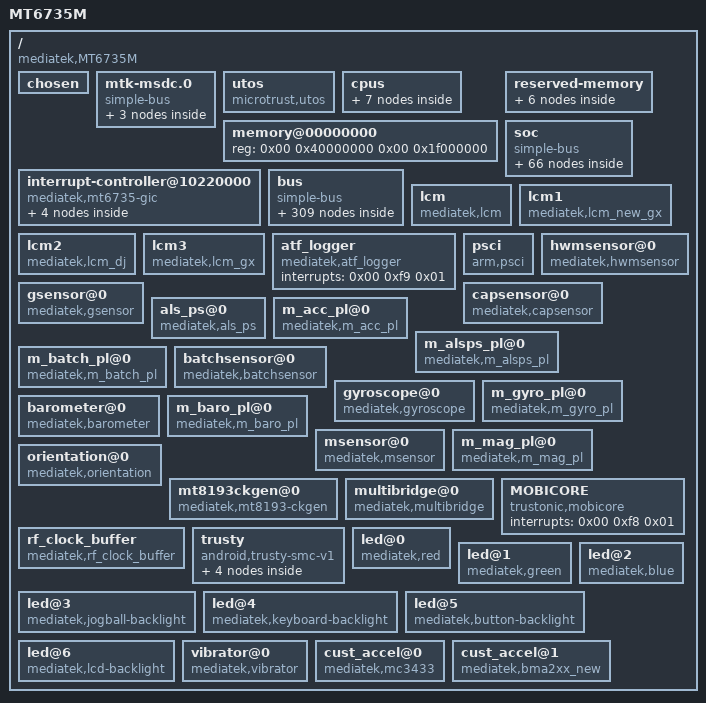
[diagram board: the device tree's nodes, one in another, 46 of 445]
/dts-v1/;

/ {
	model = "MT6735M";
	compatible = "mediatek,MT6735M";
	interrupt-parent = <0x01>;
	#address-cells = <0x02>;
	#size-cells = <0x02>;

	chosen {
		bootargs = "console=tty0 console=ttyMT0,921600n1 root=/dev/ram initrd=0x44000000,0x1000000 loglevel=8 androidboot.hardware=mt6735";
	};

	mtk-msdc.0 {
		compatible = "simple-bus";
		#address-cells = <0x01>;
		#size-cells = <0x01>;
		ranges = <0x00 0x00 0x00 0xffffffff>;

		msdc0@11230000 {
			compatible = "mediatek,mt6735m-mmc";
			reg = <0x11230000 0x10000 0x10000e84 0x02>;
			interrupts = <0x00 0x4f 0x08>;
			status = "okay";
			clk_src = [02];
			bus-width = <0x08>;
			max-frequency = <0xbebc200>;
			cap-mmc-highspeed;
			msdc-sys-suspend;
			mmc-ddr-1_8v;
			mmc-hs200-1_8v;
			mmc-hs400-1_8v;
			non-removable;
			pinctl = <0x02>;
			register_setting = <0x03>;
			host_function = [00];
			bootable;
		};

		msdc1@11240000 {
			compatible = "mediatek,mt6735m-mmc";
			reg = <0x11240000 0x10000 0x10000e84 0x02>;
			interrupts = <0x00 0x50 0x08>;
			status = "okay";
			clk_src = [02];
			bus-width = <0x04>;
			max-frequency = <0xbebc200>;
			msdc-sys-suspend;
			sd_need_power;
			cap-sd-highspeed;
			sd-uhs-sdr12;
			sd-uhs-sdr25;
			sd-uhs-sdr50;
			sd-uhs-sdr104;
			sd-uhs-ddr50;
			pinctl = <0x04>;
			pinctl_sdr104 = <0x05>;
			pinctl_sdr50 = <0x06>;
			pinctl_ddr50 = <0x07>;
			register_setting = <0x08>;
			host_function = [01];
			cd_level = [01];
			cd-gpios = <0x09 0x0b 0x00>;
		};

		default {
			compatible = "mediatek, msdc1_ins-eint";
			interrupt-parent = <0x0a>;
			interrupts = <0x0b 0x08>;
			debounce = <0x0b 0x3e8>;
			status = "okay";
		};
	};

	utos {
		compatible = "microtrust,utos";
		interrupts = <0x00 0xf4 0x01 0x00 0xf5 0x01 0x00 0xf6 0x01 0x00 0xfa 0x01 0x00 0xfb 0x01 0x00 0xfc 0x01 0x00 0xfd 0x01 0x00 0xff 0x01>;
	};

	cpus {
		#address-cells = <0x01>;
		#size-cells = <0x00>;

		cpu@000 {
			device_type = "cpu";
			compatible = "arm,cortex-a53";
			reg = <0x00>;
			enable-method = "mt-boot";
			cpu-idle-states = <0x0b 0x0b 0x0c 0x0c>;
			cpu-release-addr = <0x00 0x40000200>;
			clock-frequency = <0x3b9aca00>;
			linux,phandle = <0x0d>;
			phandle = <0x0d>;
		};

		cpu@001 {
			device_type = "cpu";
			compatible = "arm,cortex-a53";
			reg = <0x01>;
			enable-method = "mt-boot";
			cpu-idle-states = <0x0b 0x0b 0x0c 0x0c>;
			cpu-release-addr = <0x00 0x40000200>;
			clock-frequency = <0x3b9aca00>;
			linux,phandle = <0x0e>;
			phandle = <0x0e>;
		};

		cpu@002 {
			device_type = "cpu";
			compatible = "arm,cortex-a53";
			reg = <0x02>;
			enable-method = "mt-boot";
			cpu-idle-states = <0x0b 0x0b 0x0c 0x0c>;
			cpu-release-addr = <0x00 0x40000200>;
			clock-frequency = <0x3b9aca00>;
			linux,phandle = <0x0f>;
			phandle = <0x0f>;
		};

		cpu@003 {
			device_type = "cpu";
			compatible = "arm,cortex-a53";
			reg = <0x03>;
			enable-method = "mt-boot";
			cpu-idle-states = <0x0b 0x0b 0x0c 0x0c>;
			cpu-release-addr = <0x00 0x40000200>;
			clock-frequency = <0x3b9aca00>;
			linux,phandle = <0x10>;
			phandle = <0x10>;
		};

		idle-states {
			entry-method = "arm,psci";

			cpu-sleep-0-0 {
				compatible = "arm,idle-state";
				arm,psci-suspend-param = <0x10000>;
				entry-latency-us = <0x258>;
				exit-latency-us = <0x258>;
				min-residency-us = <0x4b0>;
				linux,phandle = <0x0c>;
				phandle = <0x0c>;
			};

			cluster-sleep-0 {
				compatible = "arm,idle-state";
				arm,psci-suspend-param = <0x1010000>;
				entry-latency-us = <0x320>;
				exit-latency-us = <0x3e8>;
				min-residency-us = <0x7d0>;
				linux,phandle = <0x0b>;
				phandle = <0x0b>;
			};
		};
	};

	memory@00000000 {
		device_type = "memory";
		reg = <0x00 0x40000000 0x00 0x1f000000>;
	};

	reserved-memory {
		#address-cells = <0x02>;
		#size-cells = <0x02>;
		ranges;

		atf-reserved-memory@43000000 {
			compatible = "mediatek,mt6735-atf-reserved-memory", "mediatek,mt6735m-atf-reserved-memory", "mediatek,mt6753-atf-reserved-memory";
			no-map;
			reg = <0x00 0x43000000 0x00 0x30000>;
		};

		reserve-memory-ccci_md1 {
			compatible = "mediatek,reserve-memory-ccci_md1";
			no-map;
			size = <0x00 0x3810000>;
			alignment = <0x00 0x2000000>;
			alloc-ranges = <0x00 0x40000000 0x00 0xc0000000>;
		};

		consys-reserve-memory {
			compatible = "mediatek,consys-reserve-memory";
			no-map;
			size = <0x00 0x100000>;
			alignment = <0x00 0x200000>;
		};

		ram_console-reserved-memory@43f00000 {
			compatible = "mediatek,ram_console";
			reg = <0x00 0x43f00000 0x00 0x10000>;
		};

		minirdump-reserved-memory@43ff0000 {
			compatible = "mediatek, minirdump";
			reg = <0x00 0x43ff0000 0x00 0x10000>;
		};

		pstore-reserved-memory@43f10000 {
			compatible = "mediatek,pstore";
			reg = <0x00 0x43f10000 0x00 0xe0000>;
		};
	};

	interrupt-controller@10220000 {
		compatible = "mediatek,mt6735-gic";
		#interrupt-cells = <0x03>;
		#address-cells = <0x00>;
		interrupt-controller;
		reg = <0x00 0x10221000 0x00 0x1000 0x00 0x10222000 0x00 0x1000 0x00 0x10200620 0x00 0x1000>;
		mediatek,wdt_irq = <0xa0>;
		linux,phandle = <0x01>;
		phandle = <0x01>;

		gic-cpuif@0 {
			compatible = "arm,gic-cpuif";
			cpuif-id = <0x00>;
			cpu = <0x0d>;
		};

		gic-cpuif@1 {
			compatible = "arm,gic-cpuif";
			cpuif-id = <0x01>;
			cpu = <0x0e>;
		};

		gic-cpuif@2 {
			compatible = "arm,gic-cpuif";
			cpuif-id = <0x02>;
			cpu = <0x0f>;
		};

		gic-cpuif@3 {
			compatible = "arm,gic-cpuif";
			cpuif-id = <0x03>;
			cpu = <0x10>;
		};
	};

	soc {
		compatible = "simple-bus";
		#address-cells = <0x01>;
		#size-cells = <0x01>;
		ranges;

		gpio {
			compatible = "mediatek,gpio_usage_mapping";
			GPIO_SIM1_SCLK = <0xa3>;
			GPIO_SIM1_SRST = <0xa4>;
			GPIO_SIM1_SIO = <0xa5>;
		};

		gpio@10211000 {
			compatible = "mediatek,gpio";
			reg = <0x10211000 0x1000>;
		};

		dramc_nao@1020e000 {
			compatible = "mediatek,mt6735-dramc_nao";
			reg = <0x1020e000 0x1000>;
		};

		ddrphy@10213000 {
			compatible = "mediatek,mt6735-ddrphy";
			reg = <0x10213000 0x1000>;
		};

		dramc@10214000 {
			compatible = "mediatek,mt6735-dramc";
			reg = <0x10214000 0x1000>;
			clock-names = "infra-cqdma";
		};

		cpuxgpt@10200000 {
			compatible = "mediatek,mt6735-cpuxgpt";
			reg = <0x10200000 0x1000>;
			interrupts = <0x00 0x40 0x04 0x00 0x41 0x04 0x00 0x42 0x04 0x00 0x43 0x04 0x00 0x44 0x04 0x00 0x45 0x04 0x00 0x46 0x04 0x00 0x47 0x04>;
		};

		apxgpt@10004000 {
			compatible = "mediatek,mt6735-apxgpt";
			reg = <0x10004000 0x1000>;
			interrupts = <0x00 0x98 0x08>;
			clock-frequency = <0xc65d40>;
		};

		pmu {
			compatible = "arm,armv8-pmuv3";
			interrupts = <0x00 0x08 0x08 0x00 0x09 0x08 0x00 0x0a 0x08 0x00 0x0b 0x08>;
			interrupt-affinity = <0x0d 0x0e 0x0f 0x10>;
		};

		timer {
			compatible = "arm,armv8-timer";
			interrupts = <0x01 0x0d 0x08 0x01 0x0e 0x08 0x01 0x0b 0x08 0x01 0x0a 0x08>;
			clock-frequency = <0xc65d40>;
		};

		mt_pmic_regulator {
			compatible = "mediatek,mt_pmic";

			buck_regulators {
				compatible = "mediatek,mt_pmic_buck_regulators";

				buck_vpa {
					regulator-name = "vpa";
					regulator-min-microvolt = <0x7a120>;
					regulator-max-microvolt = <0x37b1d0>;
					regulator-ramp-delay = <0xc350>;
					regulator-enable-ramp-delay = <0xb4>;
				};

				buck_vproc {
					regulator-name = "vproc";
					regulator-min-microvolt = <0x927c0>;
					regulator-max-microvolt = <0x154456>;
					regulator-ramp-delay = <0x186a>;
					regulator-enable-ramp-delay = <0xb4>;
					regulator-always-on;
					regulator-boot-on;
				};

				buck_vcore1 {
					regulator-name = "vcore1";
					regulator-min-microvolt = <0x927c0>;
					regulator-max-microvolt = <0x154456>;
					regulator-ramp-delay = <0x186a>;
					regulator-enable-ramp-delay = <0xb4>;
					regulator-always-on;
					regulator-boot-on;
				};

				buck_vsys22 {
					regulator-name = "vsys22";
					regulator-min-microvolt = <0x124f80>;
					regulator-max-microvolt = <0x1e6c16>;
					regulator-ramp-delay = <0x186a>;
					regulator-enable-ramp-delay = <0xb4>;
					regulator-always-on;
					regulator-boot-on;
				};

				buck_vlte {
					regulator-name = "vlte";
					regulator-min-microvolt = <0x927c0>;
					regulator-max-microvolt = <0x154456>;
					regulator-ramp-delay = <0x186a>;
					regulator-enable-ramp-delay = <0xb4>;
					regulator-always-on;
					regulator-boot-on;
				};
			};

			ldo_regulators {
				compatible = "mediatek,mt_pmic_ldo_regulators";

				ldo_vaux18 {
					regulator-name = "vaux18";
					regulator-min-microvolt = <0x1b7740>;
					regulator-max-microvolt = <0x1b7740>;
					regulator-enable-ramp-delay = <0x108>;
					regulator-boot-on;
					linux,phandle = <0x11>;
					phandle = <0x11>;
				};

				ldo_vtcxo_0 {
					regulator-name = "vtcxo_0";
					regulator-min-microvolt = <0x2ab980>;
					regulator-max-microvolt = <0x2ab980>;
					regulator-enable-ramp-delay = <0x6e>;
					regulator-boot-on;
					linux,phandle = <0x12>;
					phandle = <0x12>;
				};

				ldo_vtcxo_1 {
					regulator-name = "vtcxo_1";
					regulator-min-microvolt = <0x2ab980>;
					regulator-max-microvolt = <0x2ab980>;
					regulator-enable-ramp-delay = <0x6e>;
					linux,phandle = <0x13>;
					phandle = <0x13>;
				};

				ldo_vaud28 {
					regulator-name = "vaud28";
					regulator-min-microvolt = <0x2ab980>;
					regulator-max-microvolt = <0x2ab980>;
					regulator-enable-ramp-delay = <0x108>;
					regulator-boot-on;
					linux,phandle = <0x14>;
					phandle = <0x14>;
				};

				ldo_vcn28 {
					regulator-name = "vcn28";
					regulator-min-microvolt = <0x2ab980>;
					regulator-max-microvolt = <0x2ab980>;
					regulator-enable-ramp-delay = <0x108>;
					linux,phandle = <0x24>;
					phandle = <0x24>;
				};

				ldo_vcama {
					regulator-name = "vcama";
					regulator-min-microvolt = <0x16e360>;
					regulator-max-microvolt = <0x2ab980>;
					regulator-enable-ramp-delay = <0x108>;
					regulator-default-on = <0x00>;
					status = "okay";
					linux,phandle = <0x4f>;
					phandle = <0x4f>;
				};

				ldo_vcn33_bt {
					regulator-name = "vcn33_bt";
					regulator-min-microvolt = <0x325aa0>;
					regulator-max-microvolt = <0x36ee80>;
					regulator-enable-ramp-delay = <0x108>;
					linux,phandle = <0x25>;
					phandle = <0x25>;
				};

				ldo_vcn33_wifi {
					regulator-name = "vcn33_wifi";
					regulator-min-microvolt = <0x325aa0>;
					regulator-max-microvolt = <0x36ee80>;
					regulator-enable-ramp-delay = <0x108>;
					linux,phandle = <0x26>;
					phandle = <0x26>;
				};

				ldo_vusb33 {
					regulator-name = "vusb33";
					regulator-min-microvolt = <0x325aa0>;
					regulator-max-microvolt = <0x325aa0>;
					regulator-enable-ramp-delay = <0x108>;
					regulator-boot-on;
				};

				ldo_vefuse {
					regulator-name = "vefuse";
					regulator-min-microvolt = <0x1b7740>;
					regulator-max-microvolt = <0x2191c0>;
					regulator-enable-ramp-delay = <0x108>;
					linux,phandle = <0x15>;
					phandle = <0x15>;
				};

				ldo_vsim1 {
					regulator-name = "vsim1";
					regulator-min-microvolt = <0x19f0a0>;
					regulator-max-microvolt = <0x200b20>;
					regulator-enable-ramp-delay = <0x108>;
					regulator-default-on = <0x00>;
					status = "okay";
					linux,phandle = <0x16>;
					phandle = <0x16>;
				};

				ldo_vsim2 {
					regulator-name = "vsim2";
					regulator-min-microvolt = <0x19f0a0>;
					regulator-max-microvolt = <0x200b20>;
					regulator-enable-ramp-delay = <0x108>;
					regulator-default-on = <0x00>;
					status = "okay";
					linux,phandle = <0x17>;
					phandle = <0x17>;
				};

				ldo_vemc_3v3 {
					regulator-name = "vemc_3v3";
					regulator-min-microvolt = <0x1b7740>;
					regulator-max-microvolt = <0x325aa0>;
					regulator-enable-ramp-delay = <0x108>;
					regulator-boot-on;
					linux,phandle = <0x18>;
					phandle = <0x18>;
				};

				ldo_vmch {
					regulator-name = "vmch";
					regulator-min-microvolt = <0x2c4020>;
					regulator-max-microvolt = <0x325aa0>;
					regulator-enable-ramp-delay = <0x2c>;
					linux,phandle = <0x19>;
					phandle = <0x19>;
				};

				ldo_vtref {
					regulator-name = "vtref";
					regulator-min-microvolt = <0x1b7740>;
					regulator-max-microvolt = <0x1b7740>;
					regulator-enable-ramp-delay = <0xf0>;
					linux,phandle = <0x1a>;
					phandle = <0x1a>;
				};

				ldo_vmc {
					regulator-name = "vmc";
					regulator-min-microvolt = <0x1b7740>;
					regulator-max-microvolt = <0x325aa0>;
					regulator-enable-ramp-delay = <0x2c>;
					linux,phandle = <0x1b>;
					phandle = <0x1b>;
				};

				ldo_vcamaf {
					regulator-name = "vcamaf";
					regulator-min-microvolt = <0x124f80>;
					regulator-max-microvolt = <0x325aa0>;
					regulator-enable-ramp-delay = <0x108>;
					regulator-default-on = <0x00>;
					status = "okay";
					linux,phandle = <0x51>;
					phandle = <0x51>;
				};

				ldo_vio28 {
					regulator-name = "vio28";
					regulator-min-microvolt = <0x2ab980>;
					regulator-max-microvolt = <0x2ab980>;
					regulator-enable-ramp-delay = <0x108>;
					regulator-boot-on;
					linux,phandle = <0x1c>;
					phandle = <0x1c>;
				};

				ldo_vgp1 {
					regulator-name = "vgp1";
					regulator-min-microvolt = <0x124f80>;
					regulator-max-microvolt = <0x325aa0>;
					regulator-enable-ramp-delay = <0x108>;
					regulator-default-on = <0x00>;
					status = "okay";
					linux,phandle = <0x36>;
					phandle = <0x36>;
				};

				ldo_vibr {
					regulator-name = "vibr";
					regulator-min-microvolt = <0x124f80>;
					regulator-max-microvolt = <0x325aa0>;
					regulator-enable-ramp-delay = <0x2c>;
					regulator-default-on = <0x00>;
					status = "okay";
					linux,phandle = <0x1d>;
					phandle = <0x1d>;
				};

				ldo_vcamd {
					regulator-name = "vcamd";
					regulator-min-microvolt = <0xdbba0>;
					regulator-max-microvolt = <0x16e360>;
					regulator-enable-ramp-delay = <0x108>;
					regulator-default-on = <0x00>;
					status = "okay";
					linux,phandle = <0x50>;
					phandle = <0x50>;
				};

				ldo_vrf18_0 {
					regulator-name = "vrf18_0";
					regulator-min-microvolt = <0x1bd8e8>;
					regulator-max-microvolt = <0x1bd8e8>;
					regulator-enable-ramp-delay = <0xdc>;
					linux,phandle = <0x1e>;
					phandle = <0x1e>;
				};

				ldo_vrf18_1 {
					regulator-name = "vrf18_1";
					regulator-min-microvolt = <0x124f80>;
					regulator-max-microvolt = <0x1bd8e8>;
					regulator-enable-ramp-delay = <0xdc>;
					linux,phandle = <0x1f>;
					phandle = <0x1f>;
				};

				ldo_vio18 {
					regulator-name = "vio18";
					regulator-min-microvolt = <0x1b7740>;
					regulator-max-microvolt = <0x1b7740>;
					regulator-enable-ramp-delay = <0x108>;
					regulator-boot-on;
					linux,phandle = <0x20>;
					phandle = <0x20>;
				};

				ldo_vcn18 {
					regulator-name = "vcn18";
					regulator-min-microvolt = <0x1b7740>;
					regulator-max-microvolt = <0x1b7740>;
					regulator-enable-ramp-delay = <0x2c>;
					linux,phandle = <0x23>;
					phandle = <0x23>;
				};

				ldo_vcamio {
					regulator-name = "vcamio";
					regulator-min-microvolt = <0x124f80>;
					regulator-max-microvolt = <0x1b7740>;
					regulator-enable-ramp-delay = <0xdc>;
					regulator-default-on = <0x00>;
					status = "okay";
					linux,phandle = <0x52>;
					phandle = <0x52>;
				};

				ldo_vsram {
					regulator-name = "vsram";
					regulator-min-microvolt = <0xaae60>;
					regulator-max-microvolt = <0x16caf6>;
					regulator-enable-ramp-delay = <0xdc>;
					regulator-ramp-delay = <0x186a>;
					regulator-boot-on;
					linux,phandle = <0x21>;
					phandle = <0x21>;
				};

				ldo_vm {
					regulator-name = "vm";
					regulator-min-microvolt = <0x12ebc0>;
					regulator-max-microvolt = <0x177fa0>;
					regulator-enable-ramp-delay = <0x108>;
					regulator-boot-on;
					linux,phandle = <0x22>;
					phandle = <0x22>;
				};
			};

			regulators_supply {
				compatible = "mediatek,mt_pmic_regulator_supply";
				vaux18-supply = <0x11>;
				vtcxo_0-supply = <0x12>;
				vtcxo_1-supply = <0x13>;
				vaud28-supply = <0x14>;
				vefuse-supply = <0x15>;
				vsim1-supply = <0x16>;
				vsim2-supply = <0x17>;
				vemc_3v3-supply = <0x18>;
				vmch-supply = <0x19>;
				vtref-supply = <0x1a>;
				vmc-supply = <0x1b>;
				vio28-supply = <0x1c>;
				vibr-supply = <0x1d>;
				vrf18_0-supply = <0x1e>;
				vrf18_1-supply = <0x1f>;
				vio18-supply = <0x20>;
				vsram-supply = <0x21>;
				vm-supply = <0x22>;
			};
		};

		toprgu@10212000 {
			compatible = "mediatek,mt6735-rgu";
			reg = <0x10212000 0x1000>;
			interrupts = <0x00 0x80 0x02>;
		};

		mcu_biu@10300000 {
			compatible = "mediatek,mt6735-mcu_biu";
			reg = <0x10300000 0x8000>;
		};

		keypad@10003000 {
			compatible = "mediatek,mt6735-keypad", "mediatek,mt6735m-keypad";
			reg = <0x10003000 0x1000>;
			interrupts = <0x00 0xa4 0x02>;
			mediatek,kpd-key-debounce = <0x400>;
			mediatek,kpd-sw-pwrkey = <0x74>;
			mediatek,kpd-hw-pwrkey = <0x08>;
			mediatek,kpd-use-extend-type = <0x00>;
			mediatek,kpd-hw-map-num = <0x48>;
			mediatek,kpd-hw-init-map = <0x73 0x72 0x00 0x00 0x00 0x00 0x00 0x00 0x00 0x00 0x00 0x00 0x00 0x00 0x00 0x00 0x00 0x00 0x00 0x00 0x00 0x00 0x00 0x00 0x00 0x00 0x00 0x00 0x00 0x00 0x00 0x00 0x00 0x00 0x00 0x00 0x00 0x00 0x00 0x00 0x00 0x00 0x00 0x00 0x00 0x00 0x00 0x00 0x00 0x00 0x00 0x00 0x00 0x00 0x00 0x00 0x00 0x00 0x00 0x00 0x00 0x00 0x00 0x00 0x00 0x00 0x00 0x00 0x00 0x00 0x00 0x00>;
			mediatek,kpd-pwrkey-eint-gpio = <0x00>;
			mediatek,kpd-pwkey-gpio-din = <0x00>;
			mediatek,kpd-hw-dl-key0 = <0x00>;
			mediatek,kpd-hw-dl-key1 = <0x01>;
			mediatek,kpd-hw-dl-key2 = <0x08>;
			mediatek,kpd-hw-recovery-key = <0x00>;
			mediatek,kpd-hw-factory-key = <0x01>;
			status = "okay";
		};

		irtx@11011000 {
			compatible = "mediatek,irtx";
			reg = <0x11011000 0x1000>;
			interrupts = <0x00 0x7c 0x04>;
			pwm_ch = <0x00>;
		};

		apuart0@11002000 {
			cell-index = <0x00>;
			compatible = "mediatek,mt6735-uart";
			reg = <0x11002000 0x1000 0x11000380 0x1000 0x11000400 0x80>;
			interrupts = <0x00 0x5b 0x08 0x00 0x67 0x08 0x00 0x68 0x08>;
		};

		apuart1@11003000 {
			cell-index = <0x01>;
			compatible = "mediatek,mt6735-uart";
			reg = <0x11003000 0x1000 0x11000480 0x80 0x11000500 0x80>;
			interrupts = <0x00 0x5c 0x08 0x00 0x69 0x08 0x00 0x6a 0x08>;
		};

		apuart2@11004000 {
			cell-index = <0x02>;
			compatible = "mediatek,mt6735-uart";
			reg = <0x11004000 0x1000 0x11000580 0x80 0x11000600 0x80>;
			interrupts = <0x00 0x5d 0x08 0x00 0x6b 0x08 0x00 0x6c 0x08>;
		};

		apuart3@11005000 {
			cell-index = <0x03>;
			compatible = "mediatek,mt6735-uart";
			reg = <0x11005000 0x1000 0x11000680 0x80 0x11000700 0x80>;
			interrupts = <0x00 0x5e 0x08 0x00 0x6d 0x08 0x00 0x6e 0x08>;
		};

		spi@1100a000 {
			compatible = "mediatek,mt6735m-spi";
			cell-index = <0x00>;
			spi-padmacro = <0x00>;
			reg = <0x1100a000 0x1000>;
			interrupts = <0x00 0x76 0x08>;
		};

		btif_tx@11000780 {
			compatible = "mediatek,btif_tx";
			reg = <0x11000780 0x80>;
			interrupts = <0x00 0x6f 0x08>;
		};

		btif_rx@11000800 {
			compatible = "mediatek,btif_rx";
			reg = <0x11000800 0x80>;
			interrupts = <0x00 0x70 0x08>;
		};

		btif@1100c000 {
			compatible = "mediatek,btif";
			reg = <0x1100c000 0x1000>;
			interrupts = <0x00 0x5a 0x08>;
		};

		consys@18070000 {
			compatible = "mediatek,mt6735m-consys", "mediatek,mt6735-consys";
			reg = <0x18070000 0x200 0x10212000 0x100 0x10000000 0x2000 0x10006000 0x1000>;
			interrupts = <0x00 0xe3 0x08 0x00 0xe1 0x08>;
			vcn18-supply = <0x23>;
			vcn28-supply = <0x24>;
			vcn33_bt-supply = <0x25>;
			vcn33_wifi-supply = <0x26>;
			pinctrl-names = "default", "gps_lna_state_init", "gps_lna_state_oh", "gps_lna_state_ol";
			pinctrl-0 = <0x27>;
			pinctrl-1 = <0x28>;
			pinctrl-2 = <0x29>;
			pinctrl-3 = <0x2a>;
			status = "okay";
		};

		hacc@10008000 {
			compatible = "mediatek,hacc";
			reg = <0x10008000 0x1000>;
			interrupts = <0x00 0xae 0x08>;
		};

		als {
			compatible = "mediatek, als-eint";
		};

		cap_sensor {
			compatible = "mediatek, cap_sensor-eint";
			interrupt-parent = <0x0a>;
			interrupts = <0x04 0x02>;
			debounce = <0x04 0x00>;
			status = "okay";
		};

		gse_1 {
			compatible = "mediatek, gse_1-eint";
			status = "okay";
			interrupt-parent = <0x0a>;
			interrupts = <0x42 0x08>;
			debounce = <0x42 0x00>;
		};

		ext_buck_oc {
			compatible = "mediatek, ext_buck_oc-eint";
			status = "disabled";
		};

		swtp {
			compatible = "mediatek, swtp-eint";
		};

		dsi_te {
			compatible = "mediatek, dsi_te_1-eint";
			status = "disabled";
		};
	};

	bus {
		compatible = "simple-bus";
		#address-cells = <0x01>;
		#size-cells = <0x01>;
		ranges = <0x00 0x00 0x00 0xffffffff>;

		INFRACFG_AO@0x10000000 {
			compatible = "mediatek,INFRACFG_AO";
			reg = <0x10000000 0x1000>;
		};

		usb2jtag@10000000 {
			compatible = "mediatek,usb2jtag_v1";
			reg = <0x10000000 0x1000 0x11210000 0x1000>;
		};

		PWRAP@0x10001000 {
			compatible = "mediatek,PWRAP";
			reg = <0x10001000 0x1000>;
			interrupts = <0x00 0xa3 0x04>;
		};

		PERICFG@0x10002000 {
			compatible = "mediatek,PERICFG";
			reg = <0x10002000 0x1000>;
		};

		FHCTL@0x10209F00 {
			compatible = "mediatek,FHCTL";
			reg = <0x10209f00 0x100>;
		};

		KP@0x10003000 {
			compatible = "mediatek,KP";
			reg = <0x10003000 0x1000>;
			interrupts = <0x00 0xa4 0x02>;
		};

		eintc@10005000 {
			compatible = "mediatek,mt-eic";
			reg = <0x10005000 0x1000>;
			interrupts = <0x00 0x99 0x04>;
			#interrupt-cells = <0x02>;
			interrupt-controller;
			mediatek,max_eint_num = <0xd5>;
			mediatek,mapping_table_entry = <0x00>;
			mediatek,debtime_setting_entry = <0x0a>;
			mediatek,debtime_setting_array = <0x00 0x7d 0x01 0xfa 0x02 0x1f4 0x03 0x3e8 0x04 0x3e80 0x05 0x7d00 0x06 0xfa00 0x07 0x1f400 0x08 0x3e800 0x09 0x7d000>;
			linux,phandle = <0x0a>;
			phandle = <0x0a>;

			MD1_SIM1_HOT_PLUG_EINT@0 {
				compatible = "mediatek,MD1_SIM1_HOT_PLUG_EINT-eint";
				interrupts = <0x00 0x08>;
				debounce = <0x00 0x186a0>;
				dedicated = <0x00 0x00>;
				src_pin = <0x00 0x01>;
				sockettype = <0x00 0x00>;
				status = "okay";
			};

			pmic@206 {
				compatible = "mediatek, pmic-eint";
				interrupt-parent = <0x0a>;
				interrupts = <0xce 0x04>;
				debounce = <0xce 0x3e8>;
			};
		};

		SLEEP@0x10006000 {
			compatible = "mediatek,SLEEP";
			reg = <0x10006000 0x1000>;
			interrupts = <0x00 0xa5 0x08 0x00 0xa6 0x08 0x00 0xa7 0x08 0x00 0xa8 0x08>;
		};

		DEVAPC_AO@10007000 {
			compatible = "mediatek,DEVAPC_AO";
			reg = <0x10007000 0x1000>;
		};

		RSVD@0x10009000 {
			compatible = "mediatek,RSVD";
			reg = <0x10009000 0x1000>;
		};

		bat_meter {
			compatible = "mediatek,bat_meter";
			r_bat_sense = <0x04>;
			r_i_sense = <0x04>;
			r_charger_1 = <0x14a>;
			r_charger_2 = <0x27>;
			temperature_t0 = <0x6e>;
			temperature_t1 = <0x00>;
			temperature_t2 = <0x19>;
			temperature_t3 = <0x32>;
			temperature_t = <0xff>;
			fg_meter_resistance = <0x00>;
			q_max_pos_50 = <0xda7>;
			q_max_pos_25 = <0xdbb>;
			q_max_pos_0 = <0xdc3>;
			q_max_neg_10 = <0xd40>;
			q_max_pos_50_h_current = <0xd8f>;
			q_max_pos_25_h_current = <0xda2>;
			q_max_pos_0_h_current = <0xd1b>;
			q_max_neg_10_h_current = <0x83a>;
			oam_d5 = <0x00>;
			change_tracking_point = <0x01>;
			cust_tracking_point = <0x0e>;
			cust_r_sense = <0xc8>;
			cust_hw_cc = <0x00>;
			aging_tuning_value = <0x64>;
			cust_r_fg_offset = <0x00>;
			ocv_board_compesate = <0x00>;
			r_fg_board_base = <0x3e8>;
			r_fg_board_slope = <0x3e8>;
			car_tune_value = <0x63>;
			current_detect_r_fg = <0x0a>;
			minerroroffset = <0x3e8>;
			fg_vbat_average_size = <0x12>;
			r_fg_value = <0x0a>;
			cust_poweron_delta_capacity_tolrance = <0x50>;
			cust_poweron_low_capacity_tolrance = <0x02>;
			cust_poweron_max_vbat_tolrance = <0x46>;
			cust_poweron_delta_vbat_tolrance = <0x3c>;
			cust_poweron_delta_hw_sw_ocv_capacity_tolrance = <0x0a>;
			fixed_tbat_25 = <0x00>;
			vbat_normal_wakeup = <0xe10>;
			vbat_low_power_wakeup = <0xdac>;
			normal_wakeup_period = <0x1518>;
			low_power_wakeup_period = <0x12c>;
			close_poweroff_wakeup_period = <0x1e>;
			rbat_pull_up_r = <0x4204>;
			rbat_pull_up_volt = <0x708>;
			batt_temperature_table_num = <0x11>;
			batt_temperature_table = <0xffffffec 0x1104d 0xfffffff1 0xd569 0xfffffff6 0xa893 0xfffffffb 0x8627 0x00 0x6b83 0x05 0x56be 0x0a 0x466f 0x0f 0x398a 0x14 0x2f47 0x19 0x2710 0x1e 0x2072 0x23 0x1b17 0x28 0x16ba 0x2d 0x1328 0x32 0x1038 0x37 0xdcb 0x3c 0xbc8>;
			battery_profile_t0_num = <0x4b>;
			battery_profile_t0 = <0x00 0x10ef 0x03 0x10cc 0x04 0x10b5 0x06 0x10a0 0x07 0x108e 0x09 0x107d 0x0a 0x106b 0x0c 0x105b 0x0d 0x104a 0x0f 0x103a 0x10 0x102a 0x12 0x1019 0x13 0x100c 0x15 0xffe 0x16 0xff0 0x18 0xfde 0x19 0xfc6 0x1b 0xfaa 0x1c 0xf94 0x1d 0xf81 0x1f 0xf73 0x20 0xf66 0x22 0xf5c 0x23 0xf53 0x25 0xf4b 0x26 0xf43 0x28 0xf3a 0x29 0xf31 0x2b 0xf28 0x2c 0xf1f 0x2e 0xf17 0x2f 0xf0f 0x31 0xf08 0x32 0xf00 0x34 0xef9 0x35 0xef3 0x37 0xeed 0x38 0xee6 0x39 0xee1 0x3b 0xedc 0x3c 0xed8 0x3e 0xed4 0x3f 0xed1 0x41 0xecd 0x42 0xeca 0x44 0xec7 0x45 0xec4 0x47 0xec1 0x48 0xebe 0x4a 0xeba 0x4b 0xeb6 0x4d 0xeb2 0x4e 0xeae 0x50 0xea9 0x51 0xea5 0x51 0xe9f 0x53 0xe9a 0x54 0xe93 0x55 0xe8e 0x57 0xe88 0x58 0xe83 0x5a 0xe7d 0x5b 0xe76 0x5d 0xe6f 0x5e 0xe65 0x60 0xe55 0x61 0xe3d 0x63 0xe1b 0x64 0xdec 0x64 0xd48 0x64 0xd48 0x64 0xd48 0x64 0xd48 0x64 0xd48 0x64 0xd48>;
			battery_profile_t1_num = <0x4b>;
			battery_profile_t1 = <0x00 0x10f4 0x01 0x10df 0x03 0x10cc 0x04 0x10ba 0x06 0x10a9 0x07 0x109a 0x09 0x108b 0x0a 0x107b 0x0b 0x106c 0x0d 0x105e 0x0e 0x104e 0x10 0x1040 0x11 0x1030 0x12 0x1021 0x14 0x1012 0x15 0x1005 0x17 0xffa 0x18 0xff2 0x1a 0xfe5 0x1b 0xfce 0x1c 0xfaf 0x1e 0xf95 0x1f 0xf84 0x21 0xf74 0x22 0xf68 0x23 0xf5e 0x25 0xf55 0x26 0xf4d 0x28 0xf45 0x29 0xf3b 0x2b 0xf31 0x2c 0xf28 0x2d 0xf1f 0x2f 0xf17 0x30 0xf0e 0x32 0xf07 0x33 0xf00 0x35 0xefa 0x36 0xef4 0x37 0xeed 0x39 0xee8 0x3a 0xee3 0x3c 0xede 0x3d 0xed9 0x3e 0xed5 0x40 0xed1 0x41 0xecd 0x43 0xec9 0x44 0xec6 0x46 0xec4 0x47 0xec1 0x48 0xebe 0x4a 0xebb 0x4b 0xeb8 0x4d 0xeb4 0x4e 0xeb0 0x4f 0xeab 0x51 0xea5 0x52 0xe9e 0x54 0xe99 0x55 0xe92 0x57 0xe8a 0x58 0xe81 0x59 0xe7a 0x5b 0xe77 0x5c 0xe74 0x5e 0xe6f 0x5f 0xe61 0x61 0xe39 0x62 0xdfa 0x63 0xd9a 0x64 0xd48 0x64 0xd48 0x64 0xd48 0x64 0xd48>;
			battery_profile_t2_num = <0x4b>;
			battery_profile_t2 = <0x00 0x10ed 0x01 0x10da 0x03 0x10c7 0x04 0x10b7 0x06 0x10a7 0x07 0x1097 0x09 0x1087 0x0a 0x1077 0x0b 0x1068 0x0d 0x1058 0x0e 0x1049 0x10 0x103a 0x11 0x102a 0x12 0x101b 0x14 0x100c 0x15 0xffe 0x17 0xff0 0x18 0xfe8 0x1a 0xfdf 0x1b 0xfcb 0x1c 0xfb2 0x1e 0xf9e 0x1f 0xf90 0x21 0xf86 0x22 0xf81 0x24 0xf79 0x25 0xf6b 0x26 0xf5b 0x28 0xf4c 0x29 0xf3d 0x2b 0xf33 0x2c 0xf28 0x2e 0xf20 0x2f 0xf17 0x30 0xf0e 0x32 0xf07 0x33 0xf01 0x35 0xefa 0x36 0xef4 0x37 0xeef 0x39 0xee8 0x3a 0xee3 0x3c 0xede 0x3d 0xeda 0x3f 0xed6 0x40 0xed2 0x41 0xece 0x43 0xec9 0x44 0xec5 0x46 0xec0 0x47 0xeba 0x49 0xeb5 0x4a 0xeaf 0x4b 0xeaa 0x4d 0xea5 0x4e 0xea1 0x50 0xe9d 0x51 0xe98 0x53 0xe92 0x54 0xe8b 0x55 0xe84 0x57 0xe7c 0x58 0xe71 0x5a 0xe6c 0x5b 0xe6a 0x5c 0xe68 0x5e 0xe63 0x5f 0xe54 0x61 0xe26 0x62 0xde2 0x64 0xd48 0x64 0xd48 0x64 0xd48 0x64 0xd48 0x64 0xd48>;
			battery_profile_t3_num = <0x4b>;
			battery_profile_t3 = <0x00 0x10f2 0x01 0x10d3 0x03 0x10c3 0x04 0x10b3 0x06 0x10a3 0x07 0x1092 0x09 0x1083 0x0a 0x1073 0x0b 0x1063 0x0d 0x1054 0x0e 0x1044 0x10 0x1035 0x11 0x1026 0x13 0x1017 0x14 0x1009 0x15 0xffa 0x17 0xfeb 0x18 0xfdd 0x1a 0xfd1 0x1b 0xfc6 0x1d 0xfb2 0x1e 0xfa4 0x1f 0xf9c 0x21 0xf90 0x22 0xf84 0x24 0xf78 0x25 0xf69 0x27 0xf58 0x28 0xf47 0x29 0xf3a 0x2b 0xf30 0x2c 0xf26 0x2e 0xf1d 0x2f 0xf14 0x31 0xf0c 0x32 0xf05 0x34 0xefe 0x35 0xef8 0x36 0xef2 0x38 0xeeb 0x39 0xee5 0x3b 0xee0 0x3c 0xedb 0x3e 0xed6 0x3f 0xed1 0x40 0xecd 0x42 0xec9 0x43 0xec4 0x45 0xebe 0x46 0xeb4 0x48 0xeaa 0x49 0xea4 0x4a 0xe9d 0x4c 0xe96 0x4d 0xe92 0x4f 0xe8d 0x50 0xe89 0x52 0xe84 0x53 0xe7d 0x54 0xe76 0x56 0xe70 0x57 0xe68 0x59 0xe5f 0x5a 0xe5c 0x5c 0xe5b 0x5d 0xe58 0x5e 0xe52 0x60 0xe34 0x61 0xdfd 0x63 0xdb2 0x64 0xd48 0x64 0xd48 0x64 0xd48 0x64 0xd48 0x64 0xd48>;
			r_profile_t0_num = <0x4b>;
			r_profile_t0 = <0x4de 0x10ef 0x4de 0x10cc 0x4d8 0x10b5 0x4c7 0x10a0 0x4bc 0x108e 0x4ad 0x107d 0x496 0x106b 0x47d 0x105b 0x470 0x104a 0x45f 0x103a 0x459 0x102a 0x44e 0x1019 0x453 0x100c 0x44b 0xffe 0x448 0xff0 0x431 0xfde 0x40f 0xfc6 0x3eb 0xfaa 0x3d3 0xf94 0x3c2 0xf81 0x3ba 0xf73 0x3b2 0xf66 0x3b0 0xf5c 0x3ab 0xf53 0x3ae 0xf4b 0x3af 0xf43 0x3aa 0xf3a 0x3a8 0xf31 0x3a8 0xf28 0x3a7 0xf1f 0x3a4 0xf17 0x3a4 0xf0f 0x3aa 0xf08 0x3ab 0xf00 0x3ab 0xef9 0x3b2 0xef3 0x3b3 0xeed 0x3b3 0xee6 0x3b8 0xee1 0x3be 0xedc 0x3c7 0xed8 0x3ce 0xed4 0x3d3 0xed1 0x3dd 0xecd 0x3e9 0xeca 0x3f3 0xec7 0x402 0xec4 0x410 0xec1 0x420 0xebe 0x42f 0xeba 0x442 0xeb6 0x456 0xeb2 0x46d 0xeae 0x486 0xea9 0x4a3 0xea5 0x4bc 0xe9f 0x4dd 0xe9a 0x503 0xe93 0x529 0xe8e 0x559 0xe88 0x58a 0xe83 0x5c7 0xe7d 0x603 0xe76 0x643 0xe6f 0x684 0xe65 0x6c0 0xe55 0x6fd 0xe3d 0x739 0xe1b 0x788 0xdec 0x7eb 0xd48 0x7eb 0xd48 0x7eb 0xd48 0x7eb 0xd48 0x7eb 0xd48 0x7eb 0xd48>;
			r_profile_t1_num = <0x4b>;
			r_profile_t1 = <0x1fe 0x10f4 0x1fe 0x10df 0x1f9 0x10cc 0x1f5 0x10ba 0x1f0 0x10a9 0x1ed 0x109a 0x1ed 0x108b 0x1e7 0x107b 0x1df 0x106c 0x1df 0x105e 0x1d7 0x104e 0x1d6 0x1040 0x1d3 0x1030 0x1d1 0x1021 0x1cc 0x1012 0x1cb 0x1005 0x1cc 0xffa 0x1d7 0xff2 0x1db 0xfe5 0x1cb 0xfce 0x1b5 0xfaf 0x1a7 0xf95 0x1a1 0xf84 0x19f 0xf74 0x196 0xf68 0x193 0xf5e 0x193 0xf55 0x190 0xf4d 0x18b 0xf45 0x18b 0xf3b 0x186 0xf31 0x184 0xf28 0x185 0xf1f 0x187 0xf17 0x187 0xf0e 0x188 0xf07 0x18b 0xf00 0x18e 0xefa 0x192 0xef4 0x192 0xeed 0x195 0xee8 0x199 0xee3 0x199 0xede 0x1a1 0xed9 0x1a2 0xed5 0x1a6 0xed1 0x1aa 0xecd 0x1a9 0xec9 0x1ac 0xec6 0x1ad 0xec4 0x1ad 0xec1 0x1bb 0xebe 0x1be 0xebb 0x1c2 0xeb8 0x1c8 0xeb4 0x1cd 0xeb0 0x1d3 0xeab 0x1da 0xea5 0x1e1 0xe9e 0x1e4 0xe99 0x1f0 0xe92 0x1fc 0xe8a 0x203 0xe81 0x218 0xe7a 0x22e 0xe77 0x24f 0xe74 0x27c 0xe6f 0x2af 0xe61 0x2d1 0xe39 0x315 0xdfa 0x38b 0xd9a 0x47b 0xd48 0x47b 0xd48 0x47b 0xd48 0x47b 0xd48>;
			r_profile_t2_num = <0x4b>;
			r_profile_t2 = <0x9a 0x10ed 0x9a 0x10da 0x97 0x10c7 0x98 0x10b7 0x98 0x10a7 0x96 0x1097 0x96 0x1087 0x97 0x1077 0x95 0x1068 0x97 0x1058 0x98 0x1049 0x96 0x103a 0x98 0x102a 0x9a 0x101b 0x9a 0x100c 0x9b 0xffe 0x9d 0xff0 0xa4 0xfe8 0xab 0xfdf 0xa3 0xfcb 0x9d 0xfb2 0x9e 0xf9e 0xa1 0xf90 0xa4 0xf86 0xab 0xf81 0xab 0xf79 0xa6 0xf6b 0xa3 0xf5b 0x9e 0xf4c 0x98 0xf3d 0x98 0xf33 0x98 0xf28 0x98 0xf20 0x96 0xf17 0x93 0xf0e 0x95 0xf07 0x98 0xf01 0x99 0xefa 0x99 0xef4 0x9b 0xeef 0x9a 0xee8 0x9b 0xee3 0x9d 0xede 0x9e 0xeda 0xa0 0xed6 0xa1 0xed2 0xa3 0xece 0xa3 0xec9 0xa3 0xec5 0xa1 0xec0 0x9d 0xeba 0x9b 0xeb5 0x9a 0xeaf 0x9b 0xeaa 0x99 0xea5 0x9b 0xea1 0x9d 0xe9d 0x9d 0xe98 0x9e 0xe92 0x9e 0xe8b 0x9e 0xe84 0xa0 0xe7c 0x9b 0xe71 0x99 0xe6c 0x9b 0xe6a 0xa0 0xe68 0xa4 0xe63 0xa6 0xe54 0xa4 0xe26 0xae 0xde2 0xbd 0xd48 0xbd 0xd48 0xbd 0xd48 0xbd 0xd48 0xbd 0xd48>;
			r_profile_t3_num = <0x4b>;
			r_profile_t3 = <0x76 0x10f2 0x76 0x10d3 0x76 0x10c3 0x77 0x10b3 0x77 0x10a3 0x78 0x1092 0x78 0x1083 0x7a 0x1073 0x79 0x1063 0x79 0x1054 0x79 0x1044 0x79 0x1035 0x77 0x1026 0x79 0x1017 0x7a 0x1009 0x79 0xffa 0x7b 0xfeb 0x7c 0xfdd 0x7e 0xfd1 0x84 0xfc6 0x7e 0xfb2 0x82 0xfa4 0x85 0xf9c 0x84 0xf90 0x85 0xf84 0x88 0xf78 0x86 0xf69 0x7f 0xf58 0x7a 0xf47 0x77 0xf3a 0x77 0xf30 0x78 0xf26 0x79 0xf1d 0x77 0xf14 0x78 0xf0c 0x79 0xf05 0x77 0xefe 0x77 0xef8 0x7a 0xef2 0x78 0xeeb 0x79 0xee5 0x79 0xee0 0x7b 0xedb 0x7c 0xed6 0x7b 0xed1 0x7e 0xecd 0x81 0xec9 0x81 0xec4 0x7f 0xebe 0x79 0xeb4 0x78 0xeaa 0x78 0xea4 0x7b 0xe9d 0x77 0xe96 0x79 0xe92 0x79 0xe8d 0x79 0xe89 0x79 0xe84 0x79 0xe7d 0x79 0xe76 0x7b 0xe70 0x7a 0xe68 0x79 0xe5f 0x79 0xe5c 0x7c 0xe5b 0x7e 0xe58 0x82 0xe52 0x7e 0xe34 0x81 0xdfd 0x85 0xdb2 0x8f 0xd48 0x8f 0xd48 0x8f 0xd48 0x8f 0xd48 0x8f 0xd48>;
		};

		bat_meter1 {
			compatible = "mediatek,bat_meter1";
			r_bat_sense = <0x04>;
			r_i_sense = <0x04>;
			r_charger_1 = <0x14a>;
			r_charger_2 = <0x27>;
			temperature_t0 = <0x6e>;
			temperature_t1 = <0x00>;
			temperature_t2 = <0x19>;
			temperature_t3 = <0x32>;
			temperature_t = <0xff>;
			fg_meter_resistance = <0x00>;
			q_max_pos_50 = <0xde7>;
			q_max_pos_25 = <0xe00>;
			q_max_pos_0 = <0xd9c>;
			q_max_neg_10 = <0xd71>;
			q_max_pos_50_h_current = <0xdc0>;
			q_max_pos_25_h_current = <0xde8>;
			q_max_pos_0_h_current = <0xce5>;
			q_max_neg_10_h_current = <0xab0>;
			oam_d5 = <0x00>;
			change_tracking_point = <0x01>;
			cust_tracking_point = <0x0e>;
			cust_r_sense = <0xc8>;
			cust_hw_cc = <0x00>;
			aging_tuning_value = <0x64>;
			cust_r_fg_offset = <0x00>;
			ocv_board_compesate = <0x00>;
			r_fg_board_base = <0x3e8>;
			r_fg_board_slope = <0x3e8>;
			car_tune_value = <0x63>;
			current_detect_r_fg = <0x0a>;
			minerroroffset = <0x3e8>;
			fg_vbat_average_size = <0x12>;
			r_fg_value = <0x0a>;
			cust_poweron_delta_capacity_tolrance = <0x50>;
			cust_poweron_low_capacity_tolrance = <0x02>;
			cust_poweron_max_vbat_tolrance = <0x46>;
			cust_poweron_delta_vbat_tolrance = <0x3c>;
			cust_poweron_delta_hw_sw_ocv_capacity_tolrance = <0x0a>;
			fixed_tbat_25 = <0x00>;
			vbat_normal_wakeup = <0xe10>;
			vbat_low_power_wakeup = <0xdac>;
			normal_wakeup_period = <0x1518>;
			low_power_wakeup_period = <0x12c>;
			close_poweroff_wakeup_period = <0x1e>;
			rbat_pull_up_r = <0x4204>;
			rbat_pull_up_volt = <0x708>;
			batt_temperature_table_num = <0x11>;
			batt_temperature_table = <0xffffffec 0x1104d 0xfffffff1 0xd569 0xfffffff6 0xa893 0xfffffffb 0x8627 0x00 0x6b83 0x05 0x56be 0x0a 0x466f 0x0f 0x398a 0x14 0x2f47 0x19 0x2710 0x1e 0x2072 0x23 0x1b17 0x28 0x16ba 0x2d 0x1328 0x32 0x1038 0x37 0xdcb 0x3c 0xbc8>;
			battery_profile_t0_num = <0x4b>;
			battery_profile_t0 = <0x00 0x10ed 0x02 0x10d4 0x03 0x10bf 0x05 0x10ad 0x06 0x1099 0x08 0x1088 0x09 0x1076 0x0b 0x1065 0x0d 0x1054 0x0e 0x1043 0x10 0x1031 0x11 0x1021 0x13 0x1011 0x14 0x1000 0x16 0xff0 0x18 0xfe0 0x19 0xfd0 0x1b 0xfbf 0x1c 0xfac 0x1e 0xf99 0x1f 0xf88 0x21 0xf7a 0x22 0xf6c 0x24 0xf5e 0x26 0xf51 0x27 0xf45 0x29 0xf39 0x2a 0xf2d 0x2c 0xf23 0x2d 0xf19 0x2f 0xf10 0x31 0xf07 0x32 0xeff 0x34 0xef7 0x35 0xef0 0x37 0xee8 0x38 0xee3 0x3a 0xedc 0x3b 0xed7 0x3d 0xed1 0x3e 0xecc 0x40 0xec7 0x42 0xec2 0x43 0xebd 0x45 0xeba 0x46 0xeb6 0x48 0xeb3 0x49 0xeae 0x4b 0xeaa 0x4c 0xea4 0x4e 0xe9d 0x4f 0xe95 0x51 0xe8c 0x53 0xe82 0x54 0xe79 0x56 0xe73 0x57 0xe6d 0x59 0xe68 0x5a 0xe63 0x5c 0xe5e 0x5d 0xe54 0x5f 0xe39 0x60 0xe0c 0x61 0xde8 0x62 0xddd 0x62 0xdd7 0x62 0xdd2 0x63 0xdcd 0x63 0xdc7 0x63 0xdc2 0x63 0xdbc 0x64 0xdb6 0x64 0xdb0 0x64 0xdaa 0x64 0xd48>;
			battery_profile_t1_num = <0x4b>;
			battery_profile_t1 = <0x00 0x10f1 0x02 0x10db 0x03 0x10c8 0x05 0x10b7 0x06 0x10a5 0x08 0x1093 0x09 0x1082 0x0b 0x1071 0x0c 0x1060 0x0e 0x104f 0x0f 0x103e 0x11 0x102e 0x13 0x101d 0x14 0x100e 0x16 0xffe 0x17 0xfee 0x19 0xfe0 0x1a 0xfd0 0x1c 0xfbf 0x1d 0xfaf 0x1f 0xf9e 0x21 0xf8e 0x22 0xf81 0x24 0xf72 0x25 0xf64 0x27 0xf56 0x28 0xf49 0x2a 0xf3c 0x2b 0xf31 0x2d 0xf26 0x2e 0xf1c 0x30 0xf14 0x32 0xf0b 0x33 0xf04 0x35 0xefd 0x36 0xef5 0x38 0xeef 0x39 0xee9 0x3b 0xee4 0x3c 0xedf 0x3e 0xed9 0x3f 0xed4 0x41 0xed0 0x43 0xecb 0x44 0xec8 0x46 0xec3 0x47 0xec0 0x49 0xebd 0x4a 0xeb9 0x4c 0xeb5 0x4d 0xeaf 0x4f 0xea8 0x51 0xe9e 0x52 0xe94 0x54 0xe88 0x55 0xe7f 0x57 0xe78 0x58 0xe74 0x5a 0xe71 0x5b 0xe6c 0x5d 0xe68 0x5e 0xe60 0x60 0xe47 0x62 0xe16 0x63 0xdd9 0x64 0xd78 0x64 0xd48 0x64 0xd48 0x64 0xd48 0x64 0xd48 0x64 0xd48 0x64 0xd48 0x64 0xd48 0x64 0xd48 0x64 0xd48>;
			battery_profile_t2_num = <0x4b>;
			battery_profile_t2 = <0x00 0x10ed 0x02 0x10d8 0x03 0x10c6 0x05 0x10b4 0x06 0x10a2 0x08 0x1091 0x09 0x1080 0x0b 0x106f 0x0c 0x105e 0x0e 0x104e 0x0f 0x103d 0x11 0x102d 0x12 0x101e 0x14 0x100e 0x15 0xfff 0x17 0xff0 0x18 0xfe1 0x1a 0xfd3 0x1b 0xfc5 0x1d 0xfb6 0x1e 0xfa9 0x20 0xf9c 0x21 0xf90 0x23 0xf84 0x24 0xf7b 0x26 0xf6f 0x27 0xf64 0x29 0xf58 0x2a 0xf49 0x2c 0xf39 0x2d 0xf29 0x2f 0xf1b 0x30 0xf10 0x32 0xf06 0x33 0xefe 0x35 0xef6 0x36 0xef0 0x38 0xeea 0x39 0xee3 0x3b 0xede 0x3c 0xed9 0x3e 0xed5 0x3f 0xed0 0x41 0xecb 0x42 0xec8 0x44 0xec4 0x45 0xec0 0x47 0xebd 0x48 0xebb 0x4a 0xeb8 0x4b 0xeb4 0x4d 0xeb0 0x4e 0xea9 0x50 0xea4 0x51 0xe9d 0x53 0xe95 0x54 0xe89 0x56 0xe7e 0x57 0xe6f 0x59 0xe67 0x5a 0xe64 0x5c 0xe62 0x5d 0xe60 0x5f 0xe5c 0x60 0xe4f 0x62 0xe15 0x63 0xdb9 0x64 0xd48 0x64 0xd48 0x64 0xd48 0x64 0xd48 0x64 0xd48 0x64 0xd48 0x64 0xd48 0x64 0xd48>;
			battery_profile_t3_num = <0x4b>;
			battery_profile_t3 = <0x00 0x10e3 0x02 0x10cd 0x03 0x10ba 0x05 0x10a9 0x06 0x1097 0x08 0x1086 0x09 0x1075 0x0b 0x1063 0x0c 0x1053 0x0e 0x1043 0x0f 0x1033 0x11 0x1022 0x12 0x1013 0x14 0x1002 0x15 0xff3 0x17 0xfe3 0x18 0xfd4 0x1a 0xfc6 0x1b 0xfb8 0x1d 0xfaa 0x1e 0xf9d 0x20 0xf90 0x21 0xf83 0x23 0xf7a 0x24 0xf6e 0x26 0xf63 0x27 0xf59 0x29 0xf4e 0x2a 0xf42 0x2c 0xf34 0x2d 0xf22 0x2f 0xf11 0x31 0xf06 0x32 0xefd 0x34 0xef4 0x35 0xeed 0x37 0xee6 0x38 0xee0 0x3a 0xeda 0x3b 0xed4 0x3d 0xece 0x3e 0xeca 0x40 0xec4 0x41 0xec0 0x43 0xebc 0x44 0xeb8 0x46 0xeb5 0x47 0xeaf 0x49 0xea5 0x4a 0xe9d 0x4c 0xe99 0x4d 0xe93 0x4f 0xe8d 0x50 0xe86 0x52 0xe7f 0x53 0xe77 0x55 0xe69 0x56 0xe5c 0x58 0xe4f 0x59 0xe4b 0x5b 0xe4a 0x5c 0xe48 0x5e 0xe43 0x5f 0xe3b 0x61 0xe0d 0x62 0xdc1 0x64 0xd48 0x64 0xd48 0x64 0xd48 0x64 0xd48 0x64 0xd48 0x64 0xd48 0x64 0xd48 0x64 0xd48 0x64 0xd48>;
			r_profile_t0_num = <0x4b>;
			r_profile_t0 = <0x1e2 0x10ed 0x1e2 0x10d4 0x1e0 0x10bf 0x1e7 0x10ad 0x1de 0x1099 0x1e3 0x1088 0x1e5 0x1076 0x1e8 0x1065 0x1ea 0x1054 0x1ef 0x1043 0x1ea 0x1031 0x1ed 0x1021 0x1ef 0x1011 0x1ef 0x1000 0x1ef 0xff0 0x1ef 0xfe0 0x1ed 0xfd0 0x1ec 0xfbf 0x1e8 0xfac 0x1e0 0xf99 0x1e0 0xf88 0x1e0 0xf7a 0x1dd 0xf6c 0x1d9 0xf5e 0x1d6 0xf51 0x1d4 0xf45 0x1d3 0xf39 0x1d1 0xf2d 0x1d4 0xf23 0x1d3 0xf19 0x1d4 0xf10 0x1d6 0xf07 0x1d8 0xeff 0x1d8 0xef7 0x1dd 0xef0 0x1d9 0xee8 0x1dd 0xee3 0x1e0 0xedc 0x1e5 0xed7 0x1e8 0xed1 0x1e8 0xecc 0x1f1 0xec7 0x1f1 0xec2 0x1f4 0xebd 0x1f9 0xeba 0x1fb 0xeb6 0x205 0xeb3 0x206 0xeae 0x210 0xeaa 0x215 0xea4 0x21e 0xe9d 0x226 0xe95 0x230 0xe8c 0x237 0xe82 0x242 0xe79 0x250 0xe73 0x262 0xe6d 0x278 0xe68 0x296 0xe63 0x2be 0xe5e 0x2ee 0xe54 0x31b 0xe39 0x35e 0xe0c 0x3a5 0xde8 0x393 0xddd 0x389 0xdd7 0x381 0xdd2 0x378 0xdcd 0x36e 0xdc7 0x366 0xdc2 0x35c 0xdbc 0x352 0xdb6 0x348 0xdb0 0x33e 0xdaa 0x334 0xd48>;
			r_profile_t1_num = <0x4b>;
			r_profile_t1 = <0x12a 0x10f1 0x12a 0x10db 0x12e 0x10c8 0x133 0x10b7 0x133 0x10a5 0x136 0x1093 0x138 0x1082 0x139 0x1071 0x13b 0x1060 0x13e 0x104f 0x145 0x103e 0x142 0x102e 0x143 0x101d 0x148 0x100e 0x14a 0xffe 0x14a 0xfee 0x14f 0xfe0 0x14d 0xfd0 0x14d 0xfbf 0x14f 0xfaf 0x14c 0xf9e 0x147 0xf8e 0x147 0xf81 0x143 0xf72 0x13e 0xf64 0x13b 0xf56 0x138 0xf49 0x134 0xf3c 0x133 0xf31 0x133 0xf26 0x131 0xf1c 0x134 0xf14 0x133 0xf0b 0x136 0xf04 0x138 0xefd 0x136 0xef5 0x138 0xeef 0x13b 0xee9 0x13d 0xee4 0x13e 0xedf 0x140 0xed9 0x140 0xed4 0x143 0xed0 0x143 0xecb 0x145 0xec8 0x143 0xec3 0x143 0xec0 0x145 0xebd 0x147 0xeb9 0x14a 0xeb5 0x14c 0xeaf 0x14d 0xea8 0x14f 0xe9e 0x152 0xe94 0x159 0xe88 0x157 0xe7f 0x159 0xe78 0x165 0xe74 0x172 0xe71 0x183 0xe6c 0x19f 0xe68 0x1c4 0xe60 0x1ec 0xe47 0x21f 0xe16 0x26a 0xdd9 0x2d3 0xd78 0x28d 0xd48 0x28d 0xd48 0x28d 0xd48 0x28d 0xd48 0x28d 0xd48 0x28d 0xd48 0x28d 0xd48 0x28d 0xd48 0x28d 0xd48>;
			r_profile_t2_num = <0x4b>;
			r_profile_t2 = <0x57 0x10ed 0x85 0x10d8 0x89 0x10c6 0x89 0x10b4 0x8a 0x10a2 0x8c 0x1091 0x8e 0x1080 0x8e 0x106f 0x8f 0x105e 0x91 0x104e 0x93 0x103d 0x94 0x102d 0x98 0x101e 0x99 0x100e 0x9b 0xfff 0x9d 0xff0 0x9e 0xfe1 0x9d 0xfd3 0x9e 0xfc5 0xa2 0xfb6 0xa3 0xfa9 0xa5 0xf9c 0xa8 0xf90 0xaa 0xf84 0xb1 0xf7b 0xb1 0xf6f 0xb2 0xf64 0xb1 0xf58 0xaa 0xf49 0xa0 0xf39 0x96 0xf29 0x91 0xf1b 0x8e 0xf10 0x8c 0xf06 0x8c 0xefe 0x8c 0xef6 0x8f 0xef0 0x8f 0xeea 0x8f 0xee3 0x91 0xede 0x93 0xed9 0x94 0xed5 0x96 0xed0 0x96 0xecb 0x98 0xec8 0x98 0xec4 0x98 0xec0 0x98 0xebd 0x9b 0xebb 0x9b 0xeb8 0x99 0xeb4 0x98 0xeb0 0x93 0xea9 0x94 0xea4 0x93 0xe9d 0x96 0xe95 0x94 0xe89 0x96 0xe7e 0x94 0xe6f 0x91 0xe67 0x93 0xe64 0x96 0xe62 0x9e 0xe60 0xa7 0xe5c 0xb6 0xe4f 0xad 0xe15 0xbb 0xdb9 0xd5 0xd48 0xd5 0xd48 0xd5 0xd48 0xd5 0xd48 0xd5 0xd48 0xd5 0xd48 0xd5 0xd48 0xd5 0xd48>;
			r_profile_t3_num = <0x4b>;
			r_profile_t3 = <0x7b 0x10e3 0x7b 0x10cd 0x78 0x10ba 0x7b 0x10a9 0x7b 0x1097 0x7b 0x1086 0x7b 0x1075 0x7a 0x1063 0x7b 0x1053 0x7d 0x1043 0x80 0x1033 0x7f 0x1022 0x82 0x1013 0x82 0x1002 0x80 0xff3 0x84 0xfe3 0x82 0xfd4 0x82 0xfc6 0x82 0xfb8 0x82 0xfaa 0x84 0xf9d 0x84 0xf90 0x84 0xf83 0x8c 0xf7a 0x91 0xf6e 0x93 0xf63 0x96 0xf59 0x99 0xf4e 0x9b 0xf42 0x98 0xf34 0x8e 0xf22 0x82 0xf11 0x7f 0xf06 0x7f 0xefd 0x7b 0xef4 0x7b 0xeed 0x7b 0xee6 0x80 0xee0 0x80 0xeda 0x82 0xed4 0x80 0xece 0x85 0xeca 0x82 0xec4 0x87 0xec0 0x87 0xebc 0x87 0xeb8 0x8a 0xeb5 0x89 0xeaf 0x80 0xea5 0x7f 0xe9d 0x82 0xe99 0x7f 0xe93 0x80 0xe8d 0x7f 0xe86 0x80 0xe7f 0x7f 0xe77 0x7f 0xe69 0x7f 0xe5c 0x7f 0xe4f 0x7b 0xe4b 0x7d 0xe4a 0x82 0xe48 0x82 0xe43 0x8a 0xe3b 0x80 0xe0d 0x8e 0xdc1 0x94 0xd48 0x94 0xd48 0x94 0xd48 0x94 0xd48 0x94 0xd48 0x94 0xd48 0x94 0xd48 0x94 0xd48 0x94 0xd48>;
		};

		bat_notify {
			compatible = "mediatek,bat_notify";
		};

		bat_comm {
			compatible = "mediatek,battery";
			stop_charging_in_takling = <0x01>;
			talking_recharge_voltage = <0xed8>;
			talking_sync_time = <0x3c>;
			mtk_temperature_recharge_support = <0x01>;
			max_charge_temperature = <0x32>;
			max_charge_temperature_minus_x_degree = <0x2f>;
			min_charge_temperature = <0x00>;
			min_charge_temperature_plus_x_degree = <0x06>;
			err_charge_temperature = <0xff>;
			v_pre2cc_thres = <0xd48>;
			v_cc2topoff_thres = <0xfd2>;
			recharging_voltage = <0x107c>;
			charging_full_current = <0x64>;
			config_usb_if = <0x00>;
			usb_charger_current_suspend = <0x00>;
			usb_charger_current_unconfigured = <0x1b58>;
			usb_charger_current_configured = <0xc350>;
			usb_charger_current = <0xc350>;
			ac_charger_current = <0x19a28>;
			non_std_ac_charger_current = <0x186a0>;
			charging_host_charger_current = <0xfde8>;
			apple_0_5a_charger_current = <0xc350>;
			apple_1_0a_charger_current = <0xfde8>;
			apple_2_1a_charger_current = <0x13880>;
			bat_low_temp_protect_enable = <0x00>;
			v_charger_enable = <0x00>;
			v_charger_max = <0x1964>;
			v_charger_min = <0x1130>;
			onehundred_percent_tracking_time = <0x0a>;
			npercent_tracking_time = <0x14>;
			sync_to_real_tracking_time = <0x3c>;
			v_0percent_tracking = <0xd7a>;
			high_battery_voltage_support = <0x01>;
		};

		bat_id {
			compatible = "mediatek,batid";
			gpio-bat-id = <0x09 0x4d 0x00>;
		};

		mdcldma@1000A000 {
			compatible = "mediatek,mdcldma";
			reg = <0x1000a000 0x1000 0x1000b000 0x1000 0x1021a000 0x1000 0x1021b000 0x1000 0x1020a000 0x1000 0x1020b000 0x1000>;
			interrupts = <0x00 0x91 0x04 0x00 0x8c 0x08 0x00 0xdd 0x02>;
			mediatek,md_id = <0x00>;
			mediatek,cldma_capability = <0x02>;
			mediatek,md_smem_size = <0x10000>;
			pinctrl-names = "default", "vsram_output_low", "vsram_output_high", "RFIC0_01_mode", "RFIC0_04_mode";
			pinctrl-0 = <0x2b>;
			pinctrl-1 = <0x2c>;
			pinctrl-2 = <0x2d>;
			pinctrl-3 = <0x2e>;
			pinctrl-4 = <0x2f>;
		};

		dbgapb_base@1011A000 {
			compatible = "mediatek,dbgapb_base";
			reg = <0x1011a000 0x100>;
		};

		simswitch@0 {
			compatible = "mediatek,sim_switch";
			pinctrl-names = "default", "hot_plug_mode1", "hot_plug_mode2", "two_sims_bound_to_md1", "sim1_md3_sim2_md1";
			pinctrl-0 = <0x30>;
			pinctrl-1 = <0x31>;
			pinctrl-2 = <0x32>;
			pinctrl-3 = <0x33>;
			pinctrl-4 = <0x34>;
		};

		DNL3_XGPT64@0x1000C000 {
			compatible = "mediatek,DNL3_XGPT64";
			reg = <0x1000c000 0x1000>;
			interrupts = <0x00 0x9f 0x08>;
		};

		MCUCFG@0x10200000 {
			compatible = "mediatek,MCUCFG";
			reg = <0x10200000 0x200>;
			interrupts = <0x00 0x00 0x08>;
		};

		mcucfg@10200000 {
			compatible = "mediatek,mt6735-mcucfg";
			reg = <0x10200000 0x200>;
			interrupts = <0x00 0x47 0x04>;
		};

		RSVD@0x10200200 {
			compatible = "mediatek,RSVD";
			reg = <0x10200200 0x200>;
		};

		MCUSYS_MISCCFG@0x10200400 {
			compatible = "mediatek,MCUSYS_MISCCFG";
			reg = <0x10200400 0x200>;
		};

		MCUSYS_MCUCFG@0x10200600 {
			compatible = "mediatek,MCUSYS_MCUCFG";
			reg = <0x10200600 0xa00>;
		};

		INFRACFG@0x10201000 {
			compatible = "mediatek,INFRACFG";
			reg = <0x10201000 0x1000>;
		};

		SRAMROM@0x10202000 {
			compatible = "mediatek,SRAMROM";
			reg = <0x10202000 0x1000>;
		};

		EMI@0x10203000 {
			compatible = "mediatek,EMI";
			reg = <0x10203000 0x1000>;
			interrupts = <0x00 0x88 0x04>;
		};

		sys_cirq@10204000 {
			compatible = "mediatek,mt6735-sys_cirq";
			reg = <0x10204000 0x1000>;
			interrupts = <0x00 0xe7 0x08>;
			mediatek,cirq_num = <0x9f>;
			mediatek,spi_start_offset = <0x48>;
		};

		m4u@10205000 {
			cell-index = <0x00>;
			compatible = "mediatek,m4u";
			reg = <0x10205000 0x1000>;
			interrupts = <0x00 0x92 0x08>;
		};

		EFUSEC@10206000 {
			compatible = "mediatek,EFUSEC";
			reg = <0x10206000 0x1000>;
		};

		DEVAPC@10207000 {
			compatible = "mediatek,DEVAPC";
			reg = <0x10207000 0x1000>;
			interrupts = <0x00 0x86 0x08>;
		};

		bus_dbg@10208000 {
			compatible = "mediatek,bus_dbg-v1";
			reg = <0x10208000 0x1000>;
			interrupts = <0x00 0x89 0x08>;
		};

		APMIXED@0x10209000 {
			compatible = "mediatek,APMIXED";
			reg = <0x10209000 0x1000>;
		};

		RSVD@0x1020C000 {
			compatible = "mediatek,RSVD";
			reg = <0x1020c000 0x1000>;
		};

		INFRA_MBIST@0x1020D000 {
			compatible = "mediatek,INFRA_MBIST";
			reg = <0x1020d000 0x1000>;
		};

		TRNG@0x1020F000 {
			compatible = "mediatek,TRNG";
			reg = <0x1020f000 0x1000>;
			interrupts = <0x00 0x8d 0x08>;
		};

		CKSYS@0x10210000 {
			compatible = "mediatek,CKSYS";
			reg = <0x10210000 0x1000>;
		};

		MIPI_RX_ANA_CSI0@0x10215800 {
			compatible = "mediatek,MIPI_RX_ANA_CSI0";
			reg = <0x10215800 0x400>;
		};

		MIPI_RX_ANA_CSI1@0x10215C00 {
			compatible = "mediatek,MIPI_RX_ANA_CSI1";
			reg = <0x10215c00 0x400>;
		};

		gcpu@10216000 {
			compatible = "mediatek,gcpu";
			reg = <0x10216000 0x1000>;
			interrupts = <0x00 0x96 0x08>;
		};

		gce@10217000 {
			compatible = "mediatek,gce";
			reg = <0x10217000 0xc00>;
			interrupts = <0x00 0x97 0x08 0x00 0x94 0x08>;
			disp_mutex_reg = <0x14015000 0x1000>;
			g3d_config_base = <0x13000000 0x00 0xffff0000>;
			mmsys_config_base = <0x14000000 0x01 0xffff0000>;
			disp_dither_base = <0x14010000 0x02 0xffff0000>;
			mm_na_base = <0x14020000 0x03 0xffff0000>;
			imgsys_base = <0x15000000 0x04 0xffff0000>;
			vdec_gcon_base = <0x16000000 0x05 0xffff0000>;
			venc_gcon_base = <0x17000000 0x06 0xffff0000>;
			conn_peri_base = <0x18000000 0x07 0xffff0000>;
			topckgen_base = <0x10000000 0x08 0xffff0000>;
			kp_base = <0x10010000 0x09 0xffff0000>;
			scp_sram_base = <0x10020000 0x0a 0xffff0000>;
			infra_na3_base = <0x10030000 0x0b 0xffff0000>;
			infra_na4_base = <0x10040000 0x0c 0xffff0000>;
			scp_base = <0x10050000 0x0d 0xffff0000>;
			mcucfg_base = <0x10200000 0x0e 0xffff0000>;
			gcpu_base = <0x10210000 0x0f 0xffff0000>;
			usb0_base = <0x11200000 0x10 0xffff0000>;
			usb_sif_base = <0x11210000 0x11 0xffff0000>;
			audio_base = <0x11220000 0x12 0xffff0000>;
			msdc0_base = <0x11230000 0x13 0xffff0000>;
			msdc1_base = <0x11240000 0x14 0xffff0000>;
			msdc2_base = <0x11250000 0x15 0xffff0000>;
			msdc3_base = <0x11260000 0x16 0xffff0000>;
			pwm_sw_base = <0x1100e000 0x63 0xfffff000>;
			mdp_rdma0_sof = <0x00>;
			mdp_rsz0_sof = <0x01>;
			mdp_rsz1_sof = <0x02>;
			mdp_tdshp_sof = <0x03>;
			mdp_wdma_sof = <0x04>;
			mdp_wrot_sof = <0x05>;
			disp_ovl0_sof = <0x06>;
			disp_rdma0_sof = <0x08>;
			disp_rdma1_sof = <0x09>;
			disp_wdma0_sof = <0x0a>;
			disp_ccorr_sof = <0x0b>;
			disp_color_sof = <0x0c>;
			disp_aal_sof = <0x0d>;
			disp_gamma_sof = <0x0e>;
			disp_dither_sof = <0x0f>;
			disp_pwm0_sof = <0x11>;
			mdp_rdma0_frame_done = <0x12>;
			mdp_rsz0_frame_done = <0x13>;
			mdp_rsz1_frame_done = <0x14>;
			mdp_tdshp_frame_done = <0x15>;
			mdp_wdma_frame_done = <0x16>;
			mdp_wrot_write_frame_done = <0x17>;
			mdp_wrot_read_frame_done = <0x18>;
			disp_ovl0_frame_done = <0x19>;
			disp_rdma0_frame_done = <0x1b>;
			disp_rdma1_frame_done = <0x1c>;
			disp_wdma0_frame_done = <0x1d>;
			disp_ccorr_frame_done = <0x1e>;
			disp_color_frame_done = <0x1f>;
			disp_aal_frame_done = <0x20>;
			disp_gamma_frame_done = <0x21>;
			disp_dither_frame_done = <0x22>;
			disp_dpi0_frame_done = <0x24>;
			disp_dsi0_frame_done = <0x25>;
			stream_done_0 = <0x26>;
			stream_done_1 = <0x27>;
			stream_done_2 = <0x28>;
			stream_done_3 = <0x29>;
			stream_done_4 = <0x2a>;
			stream_done_5 = <0x2b>;
			stream_done_6 = <0x2c>;
			stream_done_7 = <0x2d>;
			stream_done_8 = <0x2e>;
			stream_done_9 = <0x2f>;
			buf_underrun_event_0 = <0x30>;
			buf_underrun_event_1 = <0x31>;
			dsi0_te_event = <0x32>;
			isp_frame_done_p2_1 = <0x42>;
			isp_frame_done_p2_0 = <0x43>;
			seninf_cam0_fifo_full = <0x49>;
			apxgpt2_count = <0x10004028>;
		};

		smi_larb0@14016000 {
			compatible = "mediatek,smi_larb0";
			reg = <0x14016000 0x1000>;
			interrupts = <0x00 0xb0 0x08>;
		};

		smi_larb2@15001000 {
			compatible = "mediatek,smi_larb2";
			reg = <0x15001000 0x1000>;
			interrupts = <0x00 0xb2 0x08>;
		};

		smi_common@14017000 {
			compatible = "mediatek,smi_common";
			reg = <0x14017000 0x1000 0x14016000 0x1000 0x16010000 0x1000 0x15001000 0x1000>;
		};

		smi_larb1@16010000 {
			compatible = "mediatek,smi_larb1";
			reg = <0x16010000 0x10000>;
			interrupts = <0x00 0xb1 0x08>;
		};

		cqdma@10217c00 {
			compatible = "mediatek,cqdma";
			reg = <0x10217c00 0x400>;
			interrupts = <0x00 0x8a 0x08>;
			nr_channel = <0x01>;
		};

		AP_CCIF1@0x10218000 {
			compatible = "mediatek,AP_CCIF1";
			reg = <0x10218000 0x1000>;
			interrupts = <0x00 0x8b 0x04>;
		};

		MD_CCIF1@0x10219000 {
			compatible = "mediatek,MD_CCIF1";
			reg = <0x10219000 0x1000>;
		};

		INFRA_MD@0x1021C000 {
			compatible = "mediatek,INFRA_MD";
			reg = <0x1021c000 0x1000>;
		};

		DBGAPB@0x10400000 {
			compatible = "mediatek,DBGAPB";
			reg = <0x10400000 0xc00000>;
			interrupts = <0x00 0x84 0x08>;
		};

		DEBUGTOP_CA7L@0x10800000 {
			compatible = "mediatek,DEBUGTOP_CA7L";
			reg = <0x10800000 0x400000>;
		};

		DEBUGTOP_MD1@0x10450000 {
			compatible = "mediatek,DEBUGTOP_MD1";
			reg = <0x10450000 0x20000>;
		};

		DEBUGTOP_MD2@0x10470000 {
			compatible = "mediatek,DEBUGTOP_MD2";
			reg = <0x10470000 0x10000>;
		};

		CA9@0x10220000 {
			compatible = "mediatek,CA9";
			reg = <0x10220000 0x8000>;
		};

		cpu_dbgapb {
			compatible = "mediatek,hw_dbg";
			num = <0x04>;
			reg = <0x10810000 0x1000 0x10910000 0x1000 0x10a10000 0x1000 0x10b10000 0x1000>;
		};

		dma@11000000 {
			compatible = "mediatek,ap_dma";
			reg = <0x11000000 0x1000>;
			interrupts = <0x00 0x61 0x08>;
		};

		AP_DMA_IRDA@0x11000100 {
			compatible = "mediatek,AP_DMA_IRDA";
			reg = <0x11000100 0x80>;
			interrupts = <0x00 0x62 0x08>;
		};

		adc_hw@11001000 {
			compatible = "mediatek,mt6735-auxadc";
			reg = <0x11001000 0x1000>;
			interrupts = <0x00 0x4c 0x02>;

			adc_channel@ {
				compatible = "mediatek,adc_channel";
				mediatek,temperature0 = <0x00>;
				mediatek,temperature1 = <0x01>;
				mediatek,adc_fdd_rf_params_dynamic_custom_ch = <0x0c>;
				status = "okay";
			};
		};

		PWM@0x11006000 {
			compatible = "mediatek,PWM";
			reg = <0x11006000 0x1000>;
			interrupts = <0x00 0x4d 0x08>;
		};

		G3D_CONFIG@0x13000000 {
			compatible = "mediatek,G3D_CONFIG";
			reg = <0x13000000 0x1000>;
		};

		IMGSYS@0x15000000 {
			compatible = "mediatek,IMGSYS";
			reg = <0x15000000 0x1000>;
		};

		syscfg_pctl_a@0x10211000 {
			compatible = "mediatek,mt6735-pctl-a-syscfg", "syscon";
			reg = <0x00 0x10211000 0x00 0x1000>;
			linux,phandle = <0x35>;
			phandle = <0x35>;
		};

		pinctrl@0x10211000 {
			compatible = "mediatek,mt6735-pinctrl";
			reg = <0x00 0x10211000 0x00 0x1000>;
			mediatek,pctl-regmap = <0x35>;
			pins-are-numbered;
			gpio-controller;
			#gpio-cells = <0x02>;
			linux,phandle = <0x09>;
			phandle = <0x09>;

			8193ckgen_default {
				linux,phandle = <0x60>;
				phandle = <0x60>;
			};

			8193ckgen_gpio {
				linux,phandle = <0x61>;
				phandle = <0x61>;

				pins_cmd_dat {
					pins = <0x00>;
					slew-rate = <0x01>;
					bias-pull-up = <0x00>;
					output-high;
					output-low;
				};
			};

			8193ckgen_dpi {
				linux,phandle = <0x62>;
				phandle = <0x62>;

				pins_cmd_dat {
					pins = <0x02>;
				};
			};

			ssw0default {
				linux,phandle = <0x30>;
				phandle = <0x30>;
			};

			ssw@1 {
				linux,phandle = <0x31>;
				phandle = <0x31>;

				pins_cmd0_dat {
					pins = <0x805>;
				};

				pins_cmd1_dat {
					pins = <0x904>;
				};
			};

			ssw@2 {
				linux,phandle = <0x32>;
				phandle = <0x32>;

				pins_cmd0_dat {
					pins = <0x802>;
				};

				pins_cmd1_dat {
					pins = <0x904>;
				};
			};

			ssw@3 {
				linux,phandle = <0x33>;
				phandle = <0x33>;

				pins_cmd0_dat {
					pins = <0xa301>;
					slew-rate = <0x01>;
				};

				pins_cmd1_dat {
					pins = <0xa401>;
					slew-rate = <0x01>;
				};

				pins_cmd2_dat {
					pins = <0xa501>;
					slew-rate = <0x00>;
					bias-pull-up = <0x00>;
				};

				pins_cmd3_dat {
					pins = <0xa001>;
					slew-rate = <0x01>;
				};

				pins_cmd4_dat {
					pins = <0xa101>;
					slew-rate = <0x01>;
				};

				pins_cmd5_dat {
					pins = <0xa201>;
					slew-rate = <0x00>;
					bias-pull-up = <0x00>;
				};
			};

			ssw@4 {
				linux,phandle = <0x34>;
				phandle = <0x34>;

				pins_cmd0_dat {
					pins = <0xa304>;
				};

				pins_cmd1_dat {
					pins = <0xa404>;
				};

				pins_cmd2_dat {
					pins = <0xa504>;
				};

				pins_cmd3_dat {
					pins = <0xa001>;
				};

				pins_cmd4_dat {
					pins = <0xa101>;
				};

				pins_cmd5_dat {
					pins = <0xa201>;
				};
			};

			vsram0default {
				linux,phandle = <0x2b>;
				phandle = <0x2b>;
			};

			vsram@1 {
				linux,phandle = <0x2c>;
				phandle = <0x2c>;

				pins_cmd_dat {
					pins = <0x8c00>;
					slew-rate = <0x01>;
					output-low;
				};
			};

			vsram@2 {
				linux,phandle = <0x2d>;
				phandle = <0x2d>;

				pins_cmd_dat {
					pins = <0x8c00>;
					slew-rate = <0x01>;
					output-high;
				};
			};

			clockbuf@1 {
				linux,phandle = <0x2e>;
				phandle = <0x2e>;

				pins_cmd0_dat {
					pins = <0x6e01>;
				};

				pins_cmd1_dat {
					pins = <0x6f01>;
				};

				pins_cmd2_dat {
					pins = <0x7001>;
				};

				pins_cmd3_dat {
					pins = <0x7101>;
				};

				pins_cmd4_dat {
					pins = <0x7201>;
				};
			};

			clockbuf@2 {
				linux,phandle = <0x2f>;
				phandle = <0x2f>;

				pins_cmd0_dat {
					pins = <0x6e04>;
				};

				pins_cmd1_dat {
					pins = <0x6f04>;
				};

				pins_cmd2_dat {
					pins = <0x7004>;
				};

				pins_cmd3_dat {
					pins = <0x7104>;
				};

				pins_cmd4_dat {
					pins = <0x7204>;
				};
			};

			eint0default {
				linux,phandle = <0x37>;
				phandle = <0x37>;
			};

			eint12default {
				linux,phandle = <0x3d>;
				phandle = <0x3d>;
			};

			eint12 {
				linux,phandle = <0x3e>;
				phandle = <0x3e>;

				pins_cmd_dat {
					pins = <0xc00>;
					bias-disable;
				};
			};

			eint@0 {
				linux,phandle = <0x38>;
				phandle = <0x38>;

				pins_cmd_dat {
					pins = <0xa00>;
					slew-rate = <0x00>;
					bias-disable;
				};
			};

			eintoutput0 {
				linux,phandle = <0x39>;
				phandle = <0x39>;

				pins_cmd_dat {
					pins = <0xa00>;
					slew-rate = <0x01>;
					output-low;
				};
			};

			eintoutput1 {
				linux,phandle = <0x3a>;
				phandle = <0x3a>;

				pins_cmd_dat {
					pins = <0xa00>;
					slew-rate = <0x01>;
					output-high;
				};
			};

			rstoutput0 {
				linux,phandle = <0x3b>;
				phandle = <0x3b>;

				pins_cmd_dat {
					pins = <0x3e00>;
					slew-rate = <0x01>;
					output-low;
				};
			};

			rstoutput1 {
				linux,phandle = <0x3c>;
				phandle = <0x3c>;

				pins_cmd_dat {
					pins = <0x3e00>;
					slew-rate = <0x01>;
					output-high;
				};
			};

			audiodefault {
				linux,phandle = <0x44>;
				phandle = <0x44>;
			};

			pmicclkmode0 {
				linux,phandle = <0x45>;
				phandle = <0x45>;
			};

			pmicclkmode1 {
				linux,phandle = <0x46>;
				phandle = <0x46>;
			};

			audi2s1mode0 {
				linux,phandle = <0x47>;
				phandle = <0x47>;
			};

			audi2s1mode1 {
				linux,phandle = <0x48>;
				phandle = <0x48>;
			};

			audexamphigh {
				linux,phandle = <0x49>;
				phandle = <0x49>;

				pins_cmd_dat {
					pins = <0x3d00>;
					slew-rate = <0x01>;
					output-high;
				};
			};

			audexamplow {
				linux,phandle = <0x4a>;
				phandle = <0x4a>;

				pins_cmd_dat {
					pins = <0x3d00>;
					slew-rate = <0x01>;
					output-low;
				};
			};

			audexam2phigh {
				linux,phandle = <0x4b>;
				phandle = <0x4b>;
			};

			audexamp2low {
				linux,phandle = <0x4c>;
				phandle = <0x4c>;
			};

			audrcvspkhigh {
				linux,phandle = <0x4d>;
				phandle = <0x4d>;
			};

			audrcvspklow {
				linux,phandle = <0x4e>;
				phandle = <0x4e>;
			};

			cam0@0 {
				linux,phandle = <0x54>;
				phandle = <0x54>;

				pins_cmd_dat {
					pins = <0x2c00>;
					slew-rate = <0x01>;
					output-low;
				};
			};

			cam0@1 {
				linux,phandle = <0x55>;
				phandle = <0x55>;

				pins_cmd_dat {
					pins = <0x2c00>;
					slew-rate = <0x01>;
					output-high;
				};
			};

			cam0@2 {
				linux,phandle = <0x56>;
				phandle = <0x56>;

				pins_cmd_dat {
					pins = <0x5200>;
					slew-rate = <0x01>;
					output-low;
				};
			};

			cam0@3 {
				linux,phandle = <0x57>;
				phandle = <0x57>;

				pins_cmd_dat {
					pins = <0x5200>;
					slew-rate = <0x01>;
					output-high;
				};
			};

			cam1@0 {
				linux,phandle = <0x58>;
				phandle = <0x58>;

				pins_cmd_dat {
					pins = <0x4c00>;
					slew-rate = <0x01>;
					output-low;
				};
			};

			cam1@1 {
				linux,phandle = <0x59>;
				phandle = <0x59>;

				pins_cmd_dat {
					pins = <0x4c00>;
					slew-rate = <0x01>;
					output-high;
				};
			};

			cam1@2 {
				linux,phandle = <0x5a>;
				phandle = <0x5a>;

				pins_cmd_dat {
					pins = <0x5600>;
					slew-rate = <0x01>;
					output-low;
				};
			};

			cam1@3 {
				linux,phandle = <0x5b>;
				phandle = <0x5b>;

				pins_cmd_dat {
					pins = <0x5600>;
					slew-rate = <0x01>;
					output-high;
				};
			};

			cam@0 {
				linux,phandle = <0x5c>;
				phandle = <0x5c>;
			};

			cam@1 {
				linux,phandle = <0x5d>;
				phandle = <0x5d>;
			};

			camdefault {
				linux,phandle = <0x53>;
				phandle = <0x53>;
			};

			cam_pin_gpio {
				linux,phandle = <0x5e>;
				phandle = <0x5e>;

				pins_cmd_dat {
					pins = <0x2d00>;
					slew-rate = <0x01>;
					output-low;
				};
			};

			cam_pin_mclk {
				linux,phandle = <0x5f>;
				phandle = <0x5f>;

				pins_cmd_dat {
					pins = <0x2d01>;
				};
			};

			default {
				linux,phandle = <0x27>;
				phandle = <0x27>;
			};

			gpslna@0 {
				linux,phandle = <0x28>;
				phandle = <0x28>;

				pins_cmd_dat {
					pins = <0x4f00>;
					slew-rate = <0x00>;
					bias-disable;
					output-low;
				};
			};

			gpslna@1 {
				linux,phandle = <0x29>;
				phandle = <0x29>;

				pins_cmd_dat {
					pins = <0x4f00>;
					slew-rate = <0x01>;
					output-high;
				};
			};

			gpslna@2 {
				linux,phandle = <0x2a>;
				phandle = <0x2a>;

				pins_cmd_dat {
					pins = <0x4f00>;
					slew-rate = <0x01>;
					output-low;
				};
			};

			mmc0@default {
				linux,phandle = <0x02>;
				phandle = <0x02>;

				pins_cmd {
					drive-strength = [02];
				};

				pins_dat {
					drive-strength = [02];
				};

				pins_clk {
					drive-strength = [02];
				};

				pins_rst {
					drive-strength = [02];
				};

				pins_ds {
					drive-strength = [02];
				};
			};

			mmc0@register_default {
				dat0rddly = [00];
				dat1rddly = [00];
				dat2rddly = [00];
				dat3rddly = [00];
				dat4rddly = [00];
				dat5rddly = [00];
				dat6rddly = [00];
				dat7rddly = [00];
				datwrddly = [00];
				cmdrrddly = [00];
				cmdrddly = [00];
				cmd_edge = [01];
				rdata_edge = [01];
				wdata_edge = [01];
				ett-hs200-cells = <0x0c>;
				ett-hs200-default = <0xb0 0x380 0x00 0xb0 0x7c00 0x00 0xb4 0x38 0x01 0x04 0x02 0x00 0xf0 0x1f0000 0x07 0xf0 0x7c00000 0x0b 0xb4 0x07 0x01 0xf0 0x1f 0x0b 0x04 0x400 0x00 0xf8 0x1f000000 0x07 0xf0 0x1f00 0x09 0x04 0x04 0x00>;
				ett-hs400-cells = <0x08>;
				ett-hs400-default = <0xb0 0x380 0x00 0xb0 0x7c00 0x00 0x188 0x7c 0x05 0x188 0x1f000 0x14 0xb4 0x38 0x01 0x04 0x02 0x00 0xf0 0x1f0000 0x06 0xf0 0x7c00000 0x06>;
				linux,phandle = <0x03>;
				phandle = <0x03>;
			};

			mmc1@default {
				linux,phandle = <0x04>;
				phandle = <0x04>;

				pins_cmd {
					drive-strength = [03];
				};

				pins_dat {
					drive-strength = [03];
				};

				pins_clk {
					drive-strength = [03];
				};
			};

			mmc1@sdr104 {
				linux,phandle = <0x05>;
				phandle = <0x05>;

				pins_cmd {
					drive-strength = [02];
				};

				pins_dat {
					drive-strength = [02];
				};

				pins_clk {
					drive-strength = [03];
				};
			};

			mmc1@sdr50 {
				linux,phandle = <0x06>;
				phandle = <0x06>;

				pins_cmd {
					drive-strength = [02];
				};

				pins_dat {
					drive-strength = [02];
				};

				pins_clk {
					drive-strength = [03];
				};
			};

			mmc1@ddr50 {
				linux,phandle = <0x07>;
				phandle = <0x07>;

				pins_cmd {
					drive-strength = [02];
				};

				pins_dat {
					drive-strength = [02];
				};

				pins_clk {
					drive-strength = [03];
				};
			};

			mmc1@register_default {
				dat0rddly = [00];
				dat1rddly = [00];
				dat2rddly = [00];
				dat3rddly = [00];
				datwrddly = [00];
				cmdrrddly = [00];
				cmdrddly = [00];
				cmd_edge = [01];
				rdata_edge = [01];
				wdata_edge = [01];
				linux,phandle = <0x08>;
				phandle = <0x08>;
			};

			usb_default {
				linux,phandle = <0x3f>;
				phandle = <0x3f>;
			};

			iddig_irq_init {
				linux,phandle = <0x40>;
				phandle = <0x40>;

				pins_cmd_dat {
					pins = <0x4305>;
					slew-rate = <0x00>;
					bias-pull-up = <0x00>;
				};
			};

			drvvbus_init {
				linux,phandle = <0x41>;
				phandle = <0x41>;

				pins_cmd_dat {
					pins = <0x3f00>;
					slew-rate = <0x01>;
					bias-pull-up = <0x00>;
				};
			};

			drvvbus_low {
				linux,phandle = <0x42>;
				phandle = <0x42>;

				pins_cmd_dat {
					pins = <0x3f00>;
					slew-rate = <0x01>;
					output-low;
				};
			};

			drvvbus_high {
				linux,phandle = <0x43>;
				phandle = <0x43>;

				pins_cmd_dat {
					pins = <0x3f00>;
					slew-rate = <0x01>;
					output-high;
				};
			};
		};

		i2c@11007000 {
			compatible = "mediatek,mt6735m-i2c";
			cell-index = <0x00>;
			reg = <0x11007000 0x1000>;
			interrupts = <0x00 0x54 0x08 0x00 0x63 0x08>;
			def_speed = <0x64>;
			#address-cells = <0x01>;
			#size-cells = <0x00>;

			camera_main@10 {
				compatible = "mediatek,camera_main";
				reg = <0x10>;
				status = "okay";
			};

			camera_sub@3c {
				compatible = "mediatek,camera_sub";
				reg = <0x3c>;
				status = "okay";
			};
		};

		i2c@11008000 {
			compatible = "mediatek,mt6735m-i2c";
			cell-index = <0x01>;
			reg = <0x11008000 0x1000>;
			interrupts = <0x00 0x55 0x08 0x00 0x64 0x08>;
			def_speed = <0x64>;
			#address-cells = <0x01>;
			#size-cells = <0x00>;

			cap_touch@5d {
				compatible = "mediatek,cap_touch";
				reg = <0x5d>;
				status = "okay";
			};

			CAP_TOUCH@38 {
				compatible = "mediatek,CAP_TOUCH1";
				reg = <0x38>;
			};
		};

		i2c@11009000 {
			compatible = "mediatek,mt6735m-i2c";
			cell-index = <0x02>;
			reg = <0x11009000 0x1000>;
			interrupts = <0x00 0x56 0x08 0x00 0x65 0x08>;
			def_speed = <0x64>;
			#address-cells = <0x01>;
			#size-cells = <0x00>;

			cap_sensor_2@20 {
				compatible = "mediatek,cap_sensor_2";
				reg = <0x20>;
				status = "okay";
			};

			gsensor@4c {
				compatible = "mediatek,gsensor";
				reg = <0x4c>;
				status = "okay";
			};

			cap_sensor@28 {
				compatible = "mediatek,cap_sensor";
				reg = <0x28>;
				status = "okay";
			};

			gsensor@18 {
				compatible = "mediatek,gsensor_1";
				reg = <0x18>;
			};
		};

		i2c@1100f000 {
			compatible = "mediatek,mt6735m-i2c";
			cell-index = <0x03>;
			reg = <0x1100f000 0x1000>;
			interrupts = <0x00 0x57 0x08 0x00 0x66 0x08>;
			def_speed = <0x64>;
			#address-cells = <0x01>;
			#size-cells = <0x00>;

			sm5414@49 {
				compatible = "sm,sm5414";
				reg = <0x49>;
				interrupt-parent = <0x0a>;
				interrupts = <0x44 0x02>;
				gpio_pwr_chgen = <0x09 0x7c 0x00>;
				gpio_chrg_nint = <0x09 0x44 0x00>;
				gpio_chrg_shdn = <0x09 0x3f 0x00>;
			};
		};

		SPI1@0x1100A000 {
			cell-index = <0x00>;
			spi-padmacro = <0x00>;
			compatible = "mediatek,SPI1";
			reg = <0x1100a000 0x1000>;
			interrupts = <0x00 0x76 0x08>;
		};

		touch@ {
			compatible = "mediatek,mt6735-touch", "mediatek,mt6735m-touch";
			vtouch-supply = <0x36>;
			interrupt-parent = <0x0a>;
			interrupts = <0x0a 0x02>;
			debounce = <0x0a 0x00>;
			status = "okay";
			tpd-resolution = <0x258 0x400>;
			use-tpd-button = <0x00>;
			tpd-key-num = <0x03>;
			tpd-key-local = <0x8b 0xac 0x9e 0x00>;
			tpd-key-dim-local = <0x5a 0x373 0x64 0x28 0xe6 0x373 0x64 0x28 0x172 0x373 0x64 0x28 0x00 0x00 0x00 0x00>;
			tpd-max-touch-num = <0x05>;
			tpd-filter-enable = <0x00>;
			tpd-filter-pixel-density = <0x5d>;
			tpd-filter-custom-prameters = <0x00 0x00 0x00 0x00 0x00 0x00 0x00 0x00 0x00 0x00 0x00 0x00>;
			tpd-filter-custom-speed = <0x00 0x00 0x00>;
			pinctrl-names = "default", "state_eint_as_int", "state_eint_output0", "state_eint_output1", "state_rst_output0", "state_rst_output1";
			pinctrl-0 = <0x37>;
			pinctrl-1 = <0x38>;
			pinctrl-2 = <0x39>;
			pinctrl-3 = <0x3a>;
			pinctrl-4 = <0x3b>;
			pinctrl-5 = <0x3c>;
		};

		accdet@ {
			compatible = "mediatek,mt6735-accdet", "mediatek,mt6735m-accdet";
			interrupt-parent = <0x0a>;
			interrupts = <0x0c 0x08>;
			debounce = <0x0c 0x3e800>;
			status = "okay";
			accdet-gpio = <0x09 0x0c 0x00>;
			hpswitch-gpio = <0x09 0x05 0x00>;
			accdet-mic-vol = <0x07>;
			headset-mode-setting = <0x500 0x500 0x01 0x1f0 0x800 0x800 0x20>;
			accdet-plugout-debounce = <0x14>;
			accdet-mic-mode = <0x01>;
			headset-three-key-threshold = <0x00 0x50 0xdc 0x1f4>;
			headset-three-key-threshold-CDD = <0x00 0x79 0xc0 0x258>;
			headset-four-key-threshold = <0x00 0x3a 0x79 0xc0 0x1c2>;
			pinctrl-names = "default", "state_eint_as_int";
			pinctrl-0 = <0x3d>;
			pinctrl-1 = <0x3e>;
		};

		THERM_CTRL@0x1100B000 {
			compatible = "mediatek,THERM_CTRL";
			reg = <0x1100b000 0x1000>;
			interrupts = <0x00 0x4e 0x08>;
		};

		ptp_fsm@1100b000 {
			compatible = "mediatek,ptp_fsm_v1";
			reg = <0x1100b000 0x1000>;
			interrupts = <0x00 0x7d 0x08>;
		};

		AP_DMA_BTIF_TX@0x11000780 {
			compatible = "mediatek,AP_DMA_BTIF_TX";
			reg = <0x11000780 0x80>;
			interrupts = <0x00 0x6f 0x08>;
		};

		AP_DMA_BTIF_RX@0x11000800 {
			compatible = "mediatek,AP_DMA_BTIF_RX";
			reg = <0x11000800 0x80>;
			interrupts = <0x00 0x70 0x08>;
		};

		BTIF@0x1100C000 {
			compatible = "mediatek,BTIF";
			reg = <0x1100c000 0x1000>;
			interrupts = <0x00 0x5a 0x08>;
		};

		nfc@0 {
			compatible = "mediatek,nfc-gpio-v2";
			gpio-ven = <0x04>;
			gpio-rst = <0x03>;
			gpio-eint = <0x01>;
			gpio-irq = <0x02>;
		};

		gps {
			compatible = "mediatek,gps";
		};

		btcvsd@10000000 {
			compatible = "mediatek,audio_bt_cvsd";
			offset = <0x700 0x800 0xfd0 0xfd4 0xfd8>;
			reg = <0x10000000 0x1000 0x18000000 0x10000 0x18080000 0x8000>;
			interrupts = <0x00 0xe4 0x08>;
		};

		wifi@180F0000 {
			compatible = "mediatek,wifi";
			reg = <0x180f0000 0x5c>;
			interrupts = <0x00 0xe2 0x08>;
		};

		NFI@0x1100D000 {
			compatible = "mediatek,NFI";
			reg = <0x1100d000 0x1000>;
			interrupts = <0x00 0x60 0x08>;
		};

		DISP_PWM0@0x1100E000 {
			compatible = "mediatek,DISP_PWM0";
			reg = <0x1100e000 0x1000>;
		};

		IRDA@0x11010000 {
			compatible = "mediatek,IRDA";
			reg = <0x11010000 0x1000>;
		};

		usb20@11200000 {
			compatible = "mediatek,mt6735-usb20";
			cell-index = <0x00>;
			reg = <0x11200000 0x10000 0x11210000 0x10000>;
			interrupts = <0x00 0x48 0x08>;
			mode = <0x02>;
			multipoint = <0x01>;
			dyn_fifo = <0x01>;
			soft_con = <0x01>;
			dma = <0x01>;
			num_eps = <0x10>;
			dma_channels = <0x08>;
			drvvbus_gpio = <0x53 0x02>;
			iddig_gpio = <0x43 0x01>;
			pinctrl-names = "usb_default", "iddig_irq_init", "drvvbus_init", "drvvbus_low", "drvvbus_high";
			pinctrl-0 = <0x3f>;
			pinctrl-1 = <0x40>;
			pinctrl-2 = <0x41>;
			pinctrl-3 = <0x42>;
			pinctrl-4 = <0x43>;
			status = "okay";
		};

		audio@11220000 {
			compatible = "mediatek,audio";
			reg = <0x11220000 0x10000>;
			interrupts = <0x00 0x90 0x08>;
		};

		mt_soc_dl1_pcm@11220000 {
			compatible = "mediatek,mt-soc-dl1-pcm";
			reg = <0x11220000 0x1000>;
			interrupts = <0x00 0x90 0x08>;
			audclk-gpio = <0x8f 0x00>;
			audmiso-gpio = <0x90 0x00>;
			audmosi-gpio = <0x91 0x00>;
			vowclk-gpio = <0x94 0x00>;
			extspkamp-gpio = <0x75 0x00>;
			i2s1clk-gpio = <0x50 0x00>;
			i2s1dat-gpio = <0x4e 0x00>;
			i2s1mclk-gpio = <0x09 0x00>;
			i2s1ws-gpio = <0x4f 0x00>;
			pinctrl-names = "default", "audpmicclk-mode0", "audpmicclk-mode1", "audi2s1-mode0", "audi2s1-mode1", "extamp-pullhigh", "extamp-pulllow", "extamp2-pullhigh", "extamp2-pulllow", "rcvspk-pullhigh", "rcvspk-pulllow";
			pinctrl-0 = <0x44>;
			pinctrl-1 = <0x45>;
			pinctrl-2 = <0x46>;
			pinctrl-3 = <0x47>;
			pinctrl-4 = <0x48>;
			pinctrl-5 = <0x49>;
			pinctrl-6 = <0x4a>;
			pinctrl-7 = <0x4b>;
			pinctrl-8 = <0x4c>;
			pinctrl-9 = <0x4d>;
			pinctrl-10 = <0x4e>;
			status = "okay";
		};

		mt_soc_ul1_pcm@11220000 {
			compatible = "mediatek,mt_soc_pcm_capture";
		};

		mt_soc_voice_md1@11220000 {
			compatible = "mediatek,mt_soc_pcm_voice_md1";
		};

		mt_soc_hdmi_pcm@11220000 {
			compatible = "mediatek,mt_soc_pcm_hdmi";
		};

		mt_soc_uldlloopback_pcm@11220000 {
			compatible = "mediatek,mt_soc_pcm_uldlloopback";
		};

		mt_soc_i2s0_pcm@11220000 {
			compatible = "mediatek,mt_soc_pcm_dl1_i2s0";
		};

		mt_soc_mrgrx_pcm@11220000 {
			compatible = "mediatek,mt_soc_pcm_mrgrx";
		};

		mt_soc_mrgrx_awb_pcm@11220000 {
			compatible = "mediatek,mt_soc_pcm_mrgrx_awb";
		};

		mt_soc_fm_i2s_pcm@11220000 {
			compatible = "mediatek,mt_soc_pcm_fm_i2s";
		};

		mt_soc_fm_i2s_awb_pcm@11220000 {
			compatible = "mediatek,mt_soc_pcm_fm_i2s_awb";
		};

		mt_soc_i2s0dl1_pcm@11220000 {
			compatible = "mediatek,mt_soc_pcm_dl1_i2s0Dl1";
		};

		mt_soc_dl1_awb_pcm@11220000 {
			compatible = "mediatek,mt_soc_pcm_dl1_awb";
		};

		mt_soc_voice_md1_bt@11220000 {
			compatible = "mediatek,mt_soc_pcm_voice_md1_bt";
		};

		mt_soc_voip_bt_out@11220000 {
			compatible = "mediatek,mt_soc_pcm_dl1_bt";
		};

		mt_soc_voip_bt_in@11220000 {
			compatible = "mediatek,mt_soc_pcm_bt_dai";
		};

		mt_soc_tdmrx_pcm@11220000 {
			compatible = "mediatek,mt_soc_tdm_capture";
		};

		mt_soc_fm_mrgtx_pcm@11220000 {
			compatible = "mediatek,mt_soc_pcm_fmtx";
		};

		mt_soc_ul2_pcm@11220000 {
			compatible = "mediatek,mt_soc_pcm_capture2";
		};

		mt_soc_i2s0_awb_pcm@11220000 {
			compatible = "mediatek,mt_soc_pcm_i2s0_awb";
		};

		mt_soc_voice_md2@11220000 {
			compatible = "mediatek,mt_soc_pcm_voice_md2";
		};

		mt_soc_routing_pcm@11220000 {
			compatible = "mediatek,mt_soc_pcm_routing";
			i2s1clk-gpio = <0x07 0x06>;
			i2s1dat-gpio = <0x05 0x06>;
			i2s1mclk-gpio = <0x09 0x06>;
			i2s1ws-gpio = <0x06 0x06>;
		};

		mt_soc_voice_md2_bt@11220000 {
			compatible = "mediatek,mt_soc_pcm_voice_md2_bt";
		};

		mt_soc_hp_impedance_pcm@11220000 {
			compatible = "mediatek,Mt_soc_pcm_hp_impedance";
		};

		mt_soc_codec_name@11220000 {
			compatible = "mediatek,mt_soc_codec_63xx";
		};

		mt_soc_dummy_pcm@11220000 {
			compatible = "mediatek,mt_soc_pcm_dummy";
		};

		mt_soc_codec_dummy_name@11220000 {
			compatible = "mediatek,mt_soc_codec_dummy";
		};

		mt_soc_routing_dai_name@11220000 {
			compatible = "mediatek,mt_soc_dai_routing";
		};

		mt_soc_dai_name@11220000 {
			compatible = "mediatek,mt_soc_dai_stub";
		};

		mt_soc_offload_gdma@11220000 {
			compatible = "mediatek,mt_soc_pcm_offload_gdma";
		};

		mt_soc_dl2_pcm@11220000 {
			compatible = "mediatek,mt_soc_pcm_dl2";
		};

		USB1@0x11260000 {
			compatible = "mediatek,USB1";
			reg = <0x11260000 0x10000>;
			interrupts = <0x00 0x49 0x08>;
		};

		MSDC3@0x11260000 {
			compatible = "mediatek,MSDC3";
			reg = <0x11260000 0x10000>;
		};

		WCN_AHB@0x11270000 {
			compatible = "mediatek,WCN_AHB";
			reg = <0x11270000 0x10000>;
			interrupts = <0x00 0xe4 0x08>;
		};

		MDPERIPHERALS@0x20000000 {
			compatible = "mediatek,MD PERIPHERALS";
			reg = <0x20000000 0x00>;
		};

		MD2PERIPHERALS@0x30000000 {
			compatible = "mediatek,MD2 PERIPHERALS";
			reg = <0x30000000 0x00>;
		};

		C2KPERIPHERALS@0x38000000 {
			compatible = "mediatek,C2K PERIPHERALS";
			reg = <0x38000000 0x00>;
		};

		MFGCFG@0x13000000 {
			compatible = "mediatek,MFGCFG";
			reg = <0x13000000 0x1000>;
			interrupts = <0x00 0xd2 0x08>;
		};

		MALI@0x13040000 {
			compatible = "arm,malit720", "arm,mali-t72x", "arm,malit7xx", "arm,mali-midgard";
			reg = <0x13040000 0x4000>;
			interrupts = <0x00 0xd4 0x08 0x00 0xd3 0x08 0x00 0xd2 0x08>;
			interrupt-names = "JOB", "MMU", "GPU";
			clock-frequency = <0x1ad27480>;
		};

		mmsys_config@14000000 {
			compatible = "mediatek,mmsys_config";
			reg = <0x14000000 0x1000>;
			interrupts = <0x00 0xce 0x08>;
		};

		mdp_rdma@14001000 {
			compatible = "mediatek,mdp_rdma";
			reg = <0x14001000 0x1000>;
			interrupts = <0x00 0xbb 0x08>;
		};

		mdp_rsz0@14002000 {
			compatible = "mediatek,mdp_rsz0";
			reg = <0x14002000 0x1000>;
			interrupts = <0x00 0xbc 0x08>;
		};

		mdp_rsz1@14003000 {
			compatible = "mediatek,mdp_rsz1";
			reg = <0x14003000 0x1000>;
			interrupts = <0x00 0xbd 0x08>;
		};

		mdp_wdma@14004000 {
			compatible = "mediatek,mdp_wdma";
			reg = <0x14004000 0x1000>;
			interrupts = <0x00 0xbf 0x08>;
		};

		mdp_wrot@14005000 {
			compatible = "mediatek,mdp_wrot";
			reg = <0x14005000 0x1000>;
			interrupts = <0x00 0xc0 0x08>;
		};

		mdp_tdshp@14006000 {
			compatible = "mediatek,mdp_tdshp";
			reg = <0x14006000 0x1000>;
			interrupts = <0x00 0xbe 0x08>;
		};

		DISPSYS@0x14007000 {
			compatible = "mediatek,DISPSYS";
			reg = <0x14007000 0x1000 0x00 0x00 0x14009000 0x1000 0x00 0x00 0x1400b000 0x1000 0x1400c000 0x1000 0x1400d000 0x1000 0x1400e000 0x1000 0x1400f000 0x1000 0x14010000 0x1000 0x00 0x00 0x1100e000 0x1000 0x00 0x00 0x14015000 0x1000 0x14012000 0x1000 0x14013000 0x1000 0x14000000 0x1000 0x14016000 0x1000 0x14017000 0x1000 0x14018000 0x1000 0x10206000 0x1000 0x10210000 0x1000 0x10211a70 0x0c 0x10211974 0x0c 0x10211b70 0x0c 0x10206044 0x0c 0x10206514 0x0c 0x10206558 0x0c 0x102100a0 0x1000 0x10209260 0x1000 0x10209264 0x1000 0x00 0x00 0x10209000 0x1000>;
			interrupts = <0x00 0xc1 0x08 0x00 0x00 0x08 0x00 0xc3 0x08 0x00 0x00 0x08 0x00 0xc5 0x08 0x00 0xc6 0x08 0x00 0xc7 0x08 0x00 0xc8 0x08 0x00 0xc9 0x08 0x00 0xca 0x08 0x00 0x00 0x08 0x00 0x75 0x08 0x00 0x00 0x08 0x00 0xba 0x08 0x00 0xcc 0x08 0x00 0xcd 0x08 0x00 0xce 0x08 0x00 0xb0 0x08 0x00 0x00 0x08 0x00 0x00 0x08 0x00 0x00 0x08 0x00 0x00 0x08 0x00 0x00 0x08 0x00 0x00 0x08 0x00 0x00 0x08 0x00 0x00 0x08 0x00 0x00 0x08 0x00 0x00 0x08>;
		};

		DISP_OVL0@0x14007000 {
			compatible = "mediatek,DISP_OVL0";
			reg = <0x14007000 0x1000>;
			interrupts = <0x00 0xc1 0x08>;
		};

		DISP_OVL1@0x14008000 {
			compatible = "mediatek,DISP_OVL1";
			reg = <0x14008000 0x1000>;
			interrupts = <0x00 0xc2 0x08>;
		};

		DISP_RDMA0@0x14009000 {
			compatible = "mediatek,DISP_RDMA0";
			reg = <0x14009000 0x1000>;
			interrupts = <0x00 0xc3 0x08>;
		};

		DISP_RDMA1@0x1400A000 {
			compatible = "mediatek,DISP_RDMA1";
			reg = <0x1400a000 0x1000>;
			interrupts = <0x00 0xc4 0x08>;
		};

		gpio@0x10000e00 {
			compatible = "mediatek,fpga_gpio";
			reg = <0x10000e00 0x100>;
		};

		DISP_WDMA0@0x1400B000 {
			compatible = "mediatek,DISP_WDMA0";
			reg = <0x1400b000 0x1000>;
			interrupts = <0x00 0xc5 0x08>;
		};

		DISP_COLOR@0x1400C000 {
			compatible = "mediatek,DISP_COLOR";
			reg = <0x1400c000 0x1000>;
			interrupts = <0x00 0xc6 0x08>;
		};

		DISP_CCORR@0x1400D000 {
			compatible = "mediatek,DISP_CCORR";
			reg = <0x1400d000 0x1000>;
			interrupts = <0x00 0xc7 0x08>;
		};

		DISP_AAL@0x1400E000 {
			compatible = "mediatek,DISP_AAL";
			reg = <0x1400e000 0x1000>;
			interrupts = <0x00 0xc8 0x08>;
		};

		DISP_GAMMA@0x1400F000 {
			compatible = "mediatek,DISP_GAMMA";
			reg = <0x1400f000 0x1000>;
			interrupts = <0x00 0xc9 0x08>;
		};

		DISP_DITHER@0x14010000 {
			compatible = "mediatek,DISP_DITHER";
			reg = <0x14010000 0x1000>;
			interrupts = <0x00 0xca 0x08>;
		};

		DISP_UFOE@0x14011000 {
			compatible = "mediatek,DISP_UFOE";
			reg = <0x14011000 0x1000>;
			interrupts = <0x00 0xcb 0x08>;
		};

		DSI0@0x14012000 {
			compatible = "mediatek,DSI0";
			reg = <0x14012000 0x1000>;
			interrupts = <0x00 0xcc 0x08>;
		};

		DPI0@0x14013000 {
			compatible = "mediatek,DPI0";
			reg = <0x14013000 0x1000>;
			interrupts = <0x00 0xcd 0x08>;
		};

		DISP_PWM@0x14014000 {
			compatible = "mediatek,DISP_PWM";
			reg = <0x14014000 0x1000>;
		};

		MM_MUTEX@0x14015000 {
			compatible = "mediatek,MM_MUTEX";
			reg = <0x14015000 0x1000>;
			interrupts = <0x00 0xba 0x08>;
		};

		met_smi@14017000 {
			compatible = "mediatek,met_smi";
			reg = <0x14017000 0x1000 0x14016000 0x1000 0x16010000 0x1000 0x15001000 0x1000 0x17001000 0x1000>;
		};

		MIPI_TX_CONFIG@0x14018000 {
			compatible = "mediatek,MIPI_TX_CONFIG";
			reg = <0x14018000 0x1000>;
		};

		ISPSYS@0x15000000 {
			compatible = "mediatek,ISPSYS";
			reg = <0x15004000 0x9000 0x15000000 0x10000 0x10215000 0x1000>;
			interrupts = <0x00 0xb6 0x08 0x00 0xb7 0x08>;
		};

		kd_camera_hw1@15008000 {
			compatible = "mediatek,camera_hw";
			reg = <0x15008000 0x1000>;
			vcama-supply = <0x4f>;
			vcamd-supply = <0x50>;
			vcamaf-supply = <0x51>;
			vcamio-supply = <0x52>;
			vcama_main2-supply = <0x4f>;
			vcama_sub-supply = <0x4f>;
			vcamaf_main2-supply = <0x51>;
			vcamaf_sub-supply = <0x51>;
			vcamd_main2-supply = <0x50>;
			vcamd_sub-supply = <0x50>;
			vcamio_main2-supply = <0x52>;
			vcamio_sub-supply = <0x52>;
			status = "okay";
			pinctrl-names = "default", "cam0_rst0", "cam0_rst1", "cam0_pnd0", "cam0_pnd1", "cam1_rst0", "cam1_rst1", "cam1_pnd0", "cam1_pnd1", "cam_ldo0_0", "cam_ldo0_1", "gpio_mclk", "omclk";
			pinctrl-0 = <0x53>;
			pinctrl-1 = <0x54>;
			pinctrl-2 = <0x55>;
			pinctrl-3 = <0x56>;
			pinctrl-4 = <0x57>;
			pinctrl-5 = <0x58>;
			pinctrl-6 = <0x59>;
			pinctrl-7 = <0x5a>;
			pinctrl-8 = <0x5b>;
			pinctrl-9 = <0x5c>;
			pinctrl-10 = <0x5d>;
			pinctrl-11 = <0x5e>;
			pinctrl-12 = <0x5f>;
			gpio-backcam-id = <0x09 0x00 0x00>;
			gpio-subcam-id = <0x09 0x01 0x00>;
		};

		kd_camera_hw2@15008000 {
			compatible = "mediatek,camera_hw2";
			reg = <0x15008000 0x1000>;
		};

		ISP_SYSR@0x15000000 {
			compatible = "mediatek,ISP_SYSR";
		};

		ISP_PIPEM@0x15000000 {
			compatible = "mediatek,ISP_PIPEM";
		};

		SENINF_TOP@0x15008000 {
			compatible = "mediatek,SENINF_TOP";
			reg = <0x15008000 0x1000>;
			interrupts = <0x00 0xb6 0x08>;
		};

		CAM@0x15004000 {
			compatible = "mediatek,CAM";
			reg = <0x15004000 0x1000>;
			interrupts = <0x00 0xb7 0x08>;
		};

		VENC@0x15009000 {
			compatible = "mediatek,VENC";
			reg = <0x15009000 0x1000>;
			interrupts = <0x00 0xb4 0x08>;
		};

		VDEC@0x1500B000 {
			compatible = "mediatek,VDEC";
			reg = <0x1500b000 0x1000>;
		};

		JPGENC@0x1500A000 {
			compatible = "mediatek,JPGENC";
			reg = <0x1500a000 0x1000>;
			interrupts = <0x00 0xb5 0x08>;
		};

		IMGSYS_CONFG@0x15000000 {
			compatible = "mediatek,IMGSYS_CONFG";
			reg = <0x15000000 0x1000>;
		};

		VDEC_GCON@0x16000000 {
			compatible = "mediatek,VDEC_GCON";
			reg = <0x16000000 0x1000>;
		};

		VDEC_FULL_TOP@0x16020000 {
			compatible = "mediatek,VDEC_FULL_TOP";
			reg = <0x16020000 0x10000>;
			interrupts = <0x00 0xb3 0x08>;
		};

		CHIPID@08000000 {
			compatible = "mediatek,CHIPID";
			reg = <0x8000000 0x04 0x8000004 0x04 0x8000008 0x04 0x800000c 0x04>;
		};

		pwm@11006000 {
			compatible = "mediatek,pwm";
			reg = <0x11006000 0x1000>;
			interrupts = <0x00 0x4d 0x08>;
		};

		MTKFB@5e200000 {
			compatible = "mediatek,MTKFB";
			reg = <0x7f000000 0x1000000>;
		};
	};

	lcm {
		compatible = "mediatek,lcm";
		gpio_lcd_pwr = <0x09 0x53 0x00>;
		gpio_lcd_rst = <0x09 0x92 0x00>;
	};

	lcm1 {
		compatible = "mediatek,lcm_new_gx";
		gpio_lcd_pwr = <0x09 0x53 0x00>;
		gpio_lcd_rst = <0x09 0x92 0x00>;
	};

	lcm2 {
		compatible = "mediatek,lcm_dj";
		gpio_lcd_pwr = <0x09 0x53 0x00>;
		gpio_lcd_rst = <0x09 0x92 0x00>;
	};

	lcm3 {
		compatible = "mediatek,lcm_gx";
		gpio_lcd_pwr = <0x09 0x53 0x00>;
		gpio_lcd_rst = <0x09 0x92 0x00>;
	};

	atf_logger {
		compatible = "mediatek,atf_logger";
		interrupts = <0x00 0xf9 0x01>;
	};

	psci {
		compatible = "arm,psci";
		method = "smc";
		cpu_suspend = <0x84000001>;
		cpu_off = <0x84000002>;
		cpu_on = <0x84000003>;
		affinity_info = <0x84000004>;
	};

	hwmsensor@0 {
		compatible = "mediatek,hwmsensor";
	};

	gsensor@0 {
		compatible = "mediatek,gsensor";
	};

	capsensor@0 {
		compatible = "mediatek,capsensor";
	};

	als_ps@0 {
		compatible = "mediatek,als_ps";
	};

	m_acc_pl@0 {
		compatible = "mediatek,m_acc_pl";
	};

	m_alsps_pl@0 {
		compatible = "mediatek,m_alsps_pl";
	};

	m_batch_pl@0 {
		compatible = "mediatek,m_batch_pl";
	};

	batchsensor@0 {
		compatible = "mediatek,batchsensor";
	};

	gyroscope@0 {
		compatible = "mediatek,gyroscope";
	};

	m_gyro_pl@0 {
		compatible = "mediatek,m_gyro_pl";
	};

	barometer@0 {
		compatible = "mediatek,barometer";
	};

	m_baro_pl@0 {
		compatible = "mediatek,m_baro_pl";
	};

	msensor@0 {
		compatible = "mediatek,msensor";
	};

	m_mag_pl@0 {
		compatible = "mediatek,m_mag_pl";
	};

	orientation@0 {
		compatible = "mediatek,orientation";
	};

	mt8193ckgen@0 {
		compatible = "mediatek,mt8193-ckgen";
		pinctrl-names = "default", "bus_switch_gpio", "bus_switch_dpi";
		pinctrl-0 = <0x60>;
		pinctrl-1 = <0x61>;
		pinctrl-2 = <0x62>;
		bus_switch_pin = <0x09 0x00 0x00>;
		status = "okay";
	};

	multibridge@0 {
		compatible = "mediatek,multibridge";
	};

	MOBICORE {
		compatible = "trustonic,mobicore";
		interrupts = <0x00 0xf8 0x01>;
	};

	rf_clock_buffer {
		compatible = "mediatek,rf_clock_buffer";
		mediatek,clkbuf-quantity = <0x04>;
		mediatek,clkbuf-config = <0x02 0x01 0x01 0x01>;
		status = "okay";
	};

	trusty {
		compatible = "android,trusty-smc-v1";
		ranges;
		#address-cells = <0x02>;
		#size-cells = <0x02>;

		irq {
			compatible = "android,trusty-irq-v1";
			ppi-interrupt-parent = <0x01>;
		};

		log {
			compatible = "android,trusty-log-v1";
		};

		virtio {
			compatible = "android,trusty-virtio-v1";
		};

		mtee {
			compatible = "mediatek,trusty-mtee-v1";
		};
	};

	led@0 {
		compatible = "mediatek,red";
		led_mode = <0x03>;
		data = <0x01>;
		pwm_config = <0x00 0x00 0x00 0x00 0x00>;
	};

	led@1 {
		compatible = "mediatek,green";
		led_mode = <0x03>;
		data = <0x02>;
		pwm_config = <0x00 0x00 0x00 0x00 0x00>;
	};

	led@2 {
		compatible = "mediatek,blue";
		led_mode = <0x00>;
		data = <0x01>;
		pwm_config = <0x00 0x00 0x00 0x00 0x00>;
	};

	led@3 {
		compatible = "mediatek,jogball-backlight";
		led_mode = <0x00>;
		data = <0x01>;
		pwm_config = <0x00 0x00 0x00 0x00 0x00>;
	};

	led@4 {
		compatible = "mediatek,keyboard-backlight";
		led_mode = <0x00>;
		data = <0x01>;
		pwm_config = <0x00 0x00 0x00 0x00 0x00>;
	};

	led@5 {
		compatible = "mediatek,button-backlight";
		led_mode = <0x00>;
		data = <0x01>;
		pwm_config = <0x00 0x00 0x00 0x00 0x00>;
	};

	led@6 {
		compatible = "mediatek,lcd-backlight";
		led_mode = <0x05>;
		data = <0x01>;
		pwm_config = <0x00 0x00 0x00 0x00 0x00>;
	};

	vibrator@0 {
		compatible = "mediatek,vibrator";
		vib_timer = <0x19>;
		vib_limit = <0x09>;
		vib_vol = <0x05>;
	};

	cust_accel@0 {
		compatible = "mediatek,mc3433";
		i2c_num = <0x02>;
		i2c_addr = <0x4c 0x00 0x00 0x00>;
		direction = <0x05>;
		power_id = <0xffff>;
		power_vol = <0x00>;
		firlen = <0x00>;
		is_batch_supported = <0x00>;
	};

	cust_accel@1 {
		compatible = "mediatek,bma2xx_new";
		i2c_num = <0x02>;
		i2c_addr = <0x18 0x00 0x00 0x00>;
		direction = <0x07>;
		power_id = <0xffff>;
		power_vol = <0x00>;
		firlen = <0x00>;
		is_batch_supported = <0x00>;
	};
};
